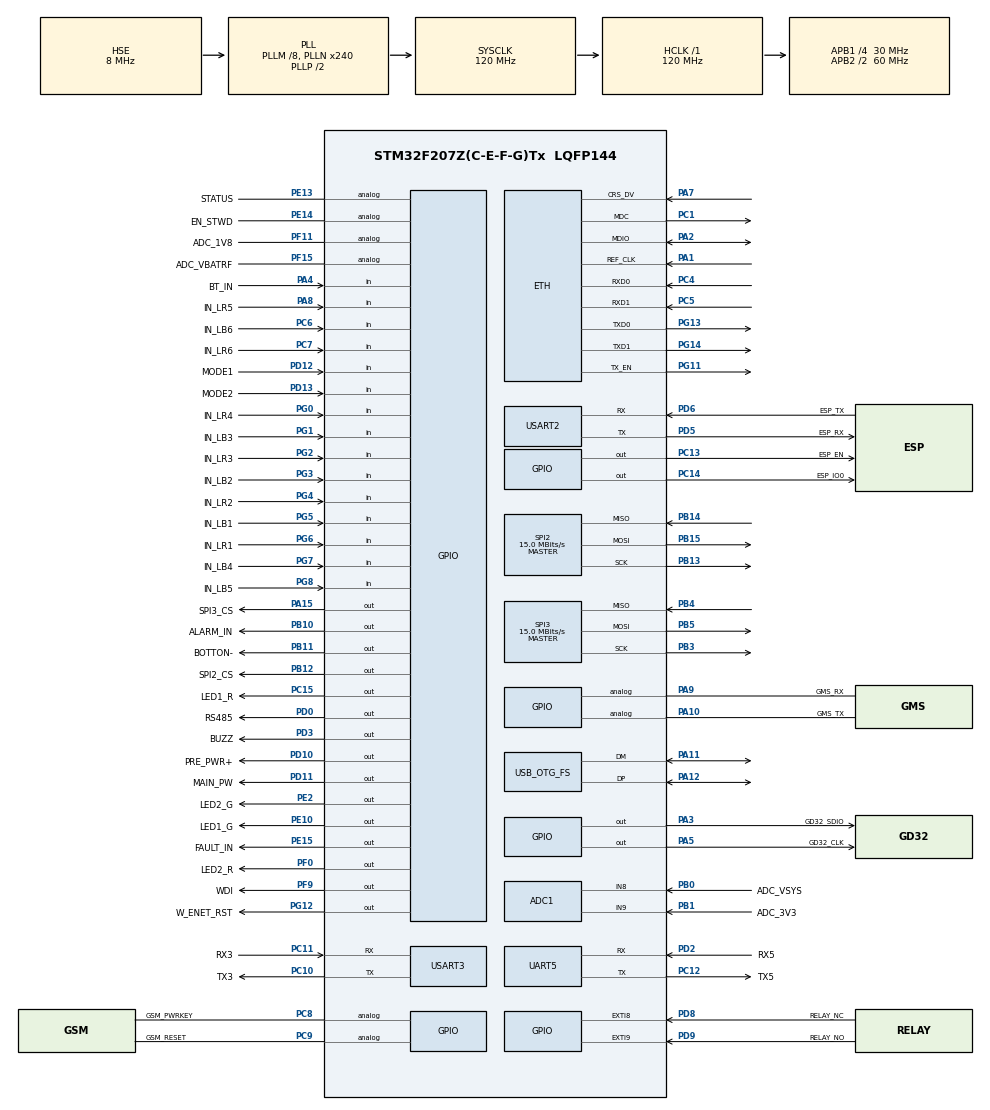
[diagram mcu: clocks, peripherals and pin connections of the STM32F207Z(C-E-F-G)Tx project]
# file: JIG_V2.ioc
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ADC1.Channel-1\#ChannelRegularConversion=ADC_CHANNEL_8
ADC1.Channel-2\#ChannelRegularConversion=ADC_CHANNEL_9
ADC1.ContinuousConvMode=ENABLE
ADC1.DMAContinuousRequests=ENABLE
ADC1.NbrOfConversion=2
ADC1.NbrOfConversionFlag=1
ADC1.Rank-1\#ChannelRegularConversion=1
ADC1.Rank-2\#ChannelRegularConversion=2
ADC1.SamplingTime-1\#ChannelRegularConversion=ADC_SAMPLETIME_480CYCLES
ADC1.SamplingTime-2\#ChannelRegularConversion=ADC_SAMPLETIME_480CYCLES
ADC1.master=1
Dma.ADC1.6.Direction=DMA_PERIPH_TO_MEMORY
Dma.ADC1.6.FIFOMode=DMA_FIFOMODE_DISABLE
Dma.ADC1.6.Instance=DMA2_Stream0
Dma.ADC1.6.MemDataAlignment=DMA_MDATAALIGN_HALFWORD
Dma.ADC1.6.MemInc=DMA_MINC_ENABLE
Dma.ADC1.6.Mode=DMA_CIRCULAR
Dma.ADC1.6.PeriphDataAlignment=DMA_PDATAALIGN_HALFWORD
Dma.ADC1.6.PeriphInc=DMA_PINC_DISABLE
Dma.ADC1.6.Priority=DMA_PRIORITY_LOW
Dma.Request0=USART2_TX
Dma.Request1=USART2_RX
Dma.Request2=SPI3_RX
Dma.Request3=SPI3_TX
Dma.Request4=SPI2_RX
Dma.Request5=SPI2_TX
Dma.Request6=ADC1
Dma.SPI2_RX.4.Direction=DMA_PERIPH_TO_MEMORY
Dma.SPI2_RX.4.FIFOMode=DMA_FIFOMODE_DISABLE
Dma.SPI2_RX.4.Instance=DMA1_Stream3
Dma.SPI2_RX.4.MemDataAlignment=DMA_MDATAALIGN_BYTE
Dma.SPI2_RX.4.MemInc=DMA_MINC_ENABLE
Dma.SPI2_RX.4.Mode=DMA_CIRCULAR
Dma.SPI2_RX.4.PeriphDataAlignment=DMA_PDATAALIGN_BYTE
Dma.SPI2_RX.4.PeriphInc=DMA_PINC_DISABLE
Dma.SPI2_RX.4.Priority=DMA_PRIORITY_LOW
Dma.SPI2_TX.5.Direction=DMA_MEMORY_TO_PERIPH
Dma.SPI2_TX.5.FIFOMode=DMA_FIFOMODE_DISABLE
Dma.SPI2_TX.5.Instance=DMA1_Stream4
Dma.SPI2_TX.5.MemDataAlignment=DMA_MDATAALIGN_BYTE
Dma.SPI2_TX.5.MemInc=DMA_MINC_ENABLE
Dma.SPI2_TX.5.Mode=DMA_NORMAL
Dma.SPI2_TX.5.PeriphDataAlignment=DMA_PDATAALIGN_BYTE
Dma.SPI2_TX.5.PeriphInc=DMA_PINC_DISABLE
Dma.SPI2_TX.5.Priority=DMA_PRIORITY_LOW
Dma.SPI3_RX.2.Direction=DMA_PERIPH_TO_MEMORY
Dma.SPI3_RX.2.FIFOMode=DMA_FIFOMODE_DISABLE
Dma.SPI3_RX.2.Instance=DMA1_Stream0
Dma.SPI3_RX.2.MemDataAlignment=DMA_MDATAALIGN_BYTE
Dma.SPI3_RX.2.MemInc=DMA_MINC_ENABLE
Dma.SPI3_RX.2.Mode=DMA_NORMAL
Dma.SPI3_RX.2.PeriphDataAlignment=DMA_PDATAALIGN_BYTE
Dma.SPI3_RX.2.PeriphInc=DMA_PINC_DISABLE
Dma.SPI3_RX.2.Priority=DMA_PRIORITY_LOW
Dma.SPI3_TX.3.Direction=DMA_MEMORY_TO_PERIPH
Dma.SPI3_TX.3.FIFOMode=DMA_FIFOMODE_DISABLE
Dma.SPI3_TX.3.Instance=DMA1_Stream7
Dma.SPI3_TX.3.MemDataAlignment=DMA_MDATAALIGN_BYTE
Dma.SPI3_TX.3.MemInc=DMA_MINC_ENABLE
Dma.SPI3_TX.3.Mode=DMA_NORMAL
Dma.SPI3_TX.3.PeriphDataAlignment=DMA_PDATAALIGN_BYTE
Dma.SPI3_TX.3.PeriphInc=DMA_PINC_DISABLE
Dma.SPI3_TX.3.Priority=DMA_PRIORITY_LOW
Dma.USART2_RX.1.Direction=DMA_PERIPH_TO_MEMORY
Dma.USART2_RX.1.FIFOMode=DMA_FIFOMODE_DISABLE
Dma.USART2_RX.1.Instance=DMA1_Stream5
Dma.USART2_RX.1.MemDataAlignment=DMA_MDATAALIGN_BYTE
Dma.USART2_RX.1.MemInc=DMA_MINC_ENABLE
Dma.USART2_RX.1.Mode=DMA_CIRCULAR
Dma.USART2_RX.1.PeriphDataAlignment=DMA_PDATAALIGN_BYTE
Dma.USART2_RX.1.PeriphInc=DMA_PINC_DISABLE
Dma.USART2_RX.1.Priority=DMA_PRIORITY_LOW
Dma.USART2_TX.0.Direction=DMA_MEMORY_TO_PERIPH
Dma.USART2_TX.0.FIFOMode=DMA_FIFOMODE_DISABLE
Dma.USART2_TX.0.Instance=DMA1_Stream6
Dma.USART2_TX.0.MemDataAlignment=DMA_MDATAALIGN_BYTE
Dma.USART2_TX.0.MemInc=DMA_MINC_ENABLE
Dma.USART2_TX.0.Mode=DMA_NORMAL
Dma.USART2_TX.0.PeriphDataAlignment=DMA_PDATAALIGN_BYTE
Dma.USART2_TX.0.PeriphInc=DMA_PINC_DISABLE
Dma.USART2_TX.0.Priority=DMA_PRIORITY_LOW
ETH.AutoNegotiation=ETH_AUTONEGOTIATION_DISABLE
ETH.MediaInterface=ETH_MEDIA_INTERFACE_RMII
ETH.PHY_Name_RMII=DP83848_PHY_ADDRESS
ETH.RxMode=ETH_RXINTERRUPT_MODE
FATFS._MAX_SS=4096
FATFS._USE_LABEL=1
FATFS._USE_LFN=2
FREERTOS.INCLUDE_vTaskDelayUntil=1
FREERTOS.Tasks01=defaultTask,0,256,StartDefaultTask,Default,NULL,Dynamic,NULL,NULL
FREERTOS.configMINIMAL_STACK_SIZE=256
FREERTOS.configTOTAL_HEAP_SIZE=48000
FREERTOS.configUSE_NEWLIB_REENTRANT=1
IWDG.Prescaler=IWDG_PRESCALER_256
IWDG.Reload=3750
LWIP.LWIP_HTTPD=1
LWIP.MEM_SIZE=1024*10
LWIP.Version=v2.0.3_Cube
Mcu.Family=STM32F2
Mcu.Name=STM32F207Z(C-E-F-G)Tx
Mcu.Package=LQFP144
NVIC.DMA1_Stream0_IRQn=true\:5\:0\:false\:false\:true\:true\:false\:true\:true
NVIC.DMA1_Stream3_IRQn=true\:5\:0\:false\:false\:true\:true\:false\:true\:true
NVIC.DMA1_Stream4_IRQn=true\:5\:0\:false\:false\:true\:true\:false\:true\:true
NVIC.DMA1_Stream5_IRQn=true\:5\:0\:false\:false\:true\:true\:false\:true\:true
NVIC.DMA1_Stream6_IRQn=true\:5\:0\:false\:false\:true\:true\:false\:true\:true
NVIC.DMA1_Stream7_IRQn=true\:5\:0\:false\:false\:true\:true\:false\:true\:true
NVIC.DMA2_Stream0_IRQn=true\:5\:0\:false\:false\:true\:true\:false\:true\:true
NVIC.ETH_IRQn=true\:5\:0\:false\:false\:true\:true\:true\:true\:true
NVIC.EXTI9_5_IRQn=true\:5\:0\:false\:false\:true\:false\:true\:true\:true
NVIC.OTG_FS_IRQn=true\:5\:0\:false\:false\:true\:true\:true\:true\:true
NVIC.PriorityGroup=NVIC_PRIORITYGROUP_4
NVIC.SPI2_IRQn=true\:5\:0\:false\:false\:true\:true\:true\:true\:true
NVIC.SPI3_IRQn=true\:5\:0\:false\:false\:true\:true\:true\:true\:true
NVIC.TIM2_IRQn=true\:15\:0\:false\:false\:true\:false\:false\:true\:true
NVIC.TimeBase=TIM2_IRQn
NVIC.TimeBaseIP=TIM2
NVIC.UART5_IRQn=true\:5\:0\:false\:false\:true\:true\:true\:true\:true
NVIC.USART2_IRQn=true\:5\:0\:false\:false\:true\:true\:true\:true\:true
NVIC.USART3_IRQn=true\:5\:0\:false\:false\:true\:true\:true\:true\:true
PA1.Mode=RMII
PA1.Signal=ETH_REF_CLK
PA10.GPIO_Label=GMS_TX
PA10.Signal=GPIO_Analog
PA11.Mode=Device_Only
PA11.Signal=USB_OTG_FS_DM
PA12.Mode=Device_Only
PA12.Signal=USB_OTG_FS_DP
PA13.Mode=Serial_Wire
PA13.Signal=SYS_JTMS-SWDIO
PA14.Mode=Serial_Wire
PA14.Signal=SYS_JTCK-SWCLK
PA15.GPIO_Label=SPI3_CS
PA15.Signal=GPIO_Output
PA2.Mode=RMII
PA2.Signal=ETH_MDIO
PA3.GPIO_Label=GD32_SDIO
PA3.Signal=GPIO_Output
PA4.GPIO_Label=BT_IN
PA4.GPIO_PuPd=GPIO_PULLUP
PA4.Signal=GPIO_Input
PA5.GPIO_Label=GD32_CLK
PA5.Signal=GPIO_Output
PA7.Mode=RMII
PA7.Signal=ETH_CRS_DV
PA8.GPIO_Label=IN_LR5
PA8.Signal=GPIO_Input
PA9.GPIO_Label=GMS_RX
PA9.Signal=GPIO_Analog
PB0.GPIO_Label=ADC_VSYS
PB0.Signal=ADCx_IN8
PB1.GPIO_Label=ADC_3V3
PB1.Signal=ADCx_IN9
PB10.GPIO_Label=ALARM_IN
PB10.Signal=GPIO_Output
PB11.GPIO_Label=BOTTON-
PB11.Signal=GPIO_Output
PB12.GPIO_Label=SPI2_CS
PB12.Signal=GPIO_Output
PB13.Mode=Full_Duplex_Master
PB13.Signal=SPI2_SCK
PB14.Mode=Full_Duplex_Master
PB14.Signal=SPI2_MISO
PB15.Mode=Full_Duplex_Master
PB15.Signal=SPI2_MOSI
PB3.Mode=Full_Duplex_Master
PB3.Signal=SPI3_SCK
PB4.Mode=Full_Duplex_Master
PB4.Signal=SPI3_MISO
PB5.Mode=Full_Duplex_Master
PB5.Signal=SPI3_MOSI
PC1.Mode=RMII
PC1.Signal=ETH_MDC
PC10.GPIO_Label=TX3
PC10.Mode=Asynchronous
PC10.Signal=USART3_TX
PC11.GPIO_Label=RX3
PC11.Mode=Asynchronous
PC11.Signal=USART3_RX
PC12.GPIO_Label=TX5
PC12.Mode=Asynchronous
PC12.Signal=UART5_TX
PC13.GPIO_Label=ESP_EN
PC13.Signal=GPIO_Output
PC14-OSC32_IN.GPIO_Label=ESP_IO0
PC14-OSC32_IN.Signal=GPIO_Output
PC15-OSC32_OUT.GPIO_Label=LED1_R
PC15-OSC32_OUT.Signal=GPIO_Output
PC4.Mode=RMII
PC4.Signal=ETH_RXD0
PC5.Mode=RMII
PC5.Signal=ETH_RXD1
PC6.GPIO_Label=IN_LB6
PC6.Signal=GPIO_Input
PC7.GPIO_Label=IN_LR6
PC7.Signal=GPIO_Input
PC8.GPIO_Label=GSM_PWRKEY
PC8.Signal=GPIO_Analog
PC9.GPIO_Label=GSM_RESET
PC9.Signal=GPIO_Analog
PD0.GPIO_Label=RS485
PD0.GPIO_PuPd=GPIO_PULLUP
PD0.Signal=GPIO_Output
PD10.GPIO_Label=PRE_PWR+
PD10.Signal=GPIO_Output
PD11.GPIO_Label=MAIN_PW
PD11.Signal=GPIO_Output
PD12.GPIO_Label=MODE1
PD12.Signal=GPIO_Input
PD13.GPIO_Label=MODE2
PD13.Signal=GPIO_Input
PD2.GPIO_Label=RX5
PD2.Mode=Asynchronous
PD2.Signal=UART5_RX
PD3.GPIO_Label=BUZZ
PD3.Signal=GPIO_Output
PD5.GPIO_Label=ESP_RX
PD5.Mode=Asynchronous
PD5.Signal=USART2_TX
PD6.GPIO_Label=ESP_TX
PD6.Mode=Asynchronous
PD6.Signal=USART2_RX
PD8.GPIO_Label=RELAY_NC
PD8.Signal=GPXTI8
PD9.GPIO_Label=RELAY_NO
PD9.Signal=GPXTI9
PE10.GPIO_Label=LED1_G
PE10.Signal=GPIO_Output
PE13.GPIO_Label=STATUS
PE13.Signal=GPIO_Analog
PE14.GPIO_Label=EN_STWD
PE14.Signal=GPIO_Analog
PE15.GPIO_Label=FAULT_IN
PE15.Signal=GPIO_Output
PE2.GPIO_Label=LED2_G
PE2.Signal=GPIO_Output
PF0.GPIO_Label=LED2_R
PF0.Signal=GPIO_Output
PF11.GPIO_Label=ADC_1V8
PF11.Signal=GPIO_Analog
PF15.GPIO_Label=ADC_VBATRF
PF15.Signal=GPIO_Analog
PF9.GPIO_Label=WDI
PF9.Signal=GPIO_Output
PG0.GPIO_Label=IN_LR4
PG0.Signal=GPIO_Input
PG1.GPIO_Label=IN_LB3
PG1.Signal=GPIO_Input
PG11.Mode=RMII
PG11.Signal=ETH_TX_EN
PG12.GPIO_Label=W_ENET_RST
PG12.GPIO_PuPd=GPIO_PULLUP
PG12.PinState=GPIO_PIN_SET
PG12.Signal=GPIO_Output
PG13.Mode=RMII
PG13.Signal=ETH_TXD0
PG14.Mode=RMII
PG14.Signal=ETH_TXD1
PG2.GPIO_Label=IN_LR3
PG2.Signal=GPIO_Input
PG3.GPIO_Label=IN_LB2
PG3.Signal=GPIO_Input
PG4.GPIO_Label=IN_LR2
PG4.Signal=GPIO_Input
PG5.GPIO_Label=IN_LB1
PG5.Signal=GPIO_Input
PG6.GPIO_Label=IN_LR1
PG6.Signal=GPIO_Input
PG7.GPIO_Label=IN_LB4
PG7.Signal=GPIO_Input
PG8.GPIO_Label=IN_LB5
PG8.Signal=GPIO_Input
PH0-OSC_IN.Mode=HSE-External-Oscillator
PH0-OSC_IN.Signal=RCC_OSC_IN
PH1-OSC_OUT.Mode=HSE-External-Oscillator
PH1-OSC_OUT.Signal=RCC_OSC_OUT
ProjectManager.HeapSize=0x200
ProjectManager.StackSize=0x400
ProjectManager.TargetToolchain=STM32CubeIDE
RCC.48MHZClocksFreq_Value=48000000
RCC.AHBFreq_Value=120000000
RCC.APB1CLKDivider=RCC_HCLK_DIV4
RCC.APB1Freq_Value=30000000
RCC.APB1TimFreq_Value=60000000
RCC.APB2CLKDivider=RCC_HCLK_DIV2
RCC.APB2Freq_Value=60000000
RCC.APB2TimFreq_Value=120000000
RCC.CortexFreq_Value=120000000
RCC.HCLKFreq_Value=120000000
RCC.HSE_VALUE=8000000
RCC.HSI_VALUE=16000000
RCC.LSE_VALUE=32768
RCC.PLLM=8
RCC.PLLN=240
RCC.PLLQ=5
RCC.PLLSourceVirtual=RCC_PLLSOURCE_HSE
RCC.SYSCLKFreq_VALUE=120000000
RCC.SYSCLKSource=RCC_SYSCLKSOURCE_PLLCLK
RCC.VCOOutputFreq_Value=240000000
RTC.AsynchPrediv=125
SH.ADCx_IN8.0=ADC1_IN8,IN8
SH.ADCx_IN9.0=ADC1_IN9,IN9
SPI2.CalculateBaudRate=15.0 MBits/s
SPI2.Direction=SPI_DIRECTION_2LINES
SPI2.Mode=SPI_MODE_MASTER
SPI2.VirtualType=VM_MASTER
SPI3.CalculateBaudRate=15.0 MBits/s
SPI3.Direction=SPI_DIRECTION_2LINES
SPI3.Mode=SPI_MODE_MASTER
SPI3.VirtualType=VM_MASTER
UART5.VirtualMode=Asynchronous
USART2.VirtualMode=VM_ASYNC
USART3.VirtualMode=VM_ASYNC
USB_DEVICE.CLASS_NAME_FS=MSC
USB_DEVICE.VirtualMode-MSC_FS=Msc
USB_DEVICE.VirtualModeFS=Msc_FS
USB_OTG_FS.VirtualMode=Device_Only
VP_FATFS_VS_Generic.Mode=User_defined
VP_FREERTOS_VS_CMSIS_V1.Mode=CMSIS_V1
VP_IWDG_VS_IWDG.Mode=IWDG_Activate
VP_LWIP_VS_Enabled.Mode=Enabled
VP_RTC_VS_RTC_Activate.Mode=RTC_Enabled
VP_RTC_VS_RTC_Calendar.Mode=RTC_Calendar
VP_SYS_VS_tim2.Mode=TIM2
VP_USB_DEVICE_VS_USB_DEVICE_MSC_FS.Mode=MSC_FS
board=custom

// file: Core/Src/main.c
/* USER CODE BEGIN Header */
/**
  ******************************************************************************
  * @file           : main.c
  * @brief          : Main program body
  ******************************************************************************
  * @attention
  *
  * Copyright (c) 2022 STMicroelectronics.
  * All rights reserved.
  *
  * This software is licensed under terms that can be found in the LICENSE file
  * in the root directory of this software component.
  * If no LICENSE file comes with this software, it is provided AS-IS.
  *
  ******************************************************************************
  */
/* USER CODE END Header */
#include "main.h"
#include "cmsis_os.h"
#include "adc.h"
#include "dma.h"
#include "fatfs.h"
#include "iwdg.h"
#include "lwip.h"
#include "rtc.h"
#include "spi.h"
#include "usart.h"
#include "usb_device.h"
#include "gpio.h"

/* USER CODE BEGIN Includes */
#include <stdbool.h>
#include "app_debug.h"
#include "Segger_RTT.h"
/* USER CODE END Includes */

/* USER CODE BEGIN PV */
uint16_t toggle_100_ms = 0;
/* USER CODE END PV */

void SystemClock_Config(void);
void MX_FREERTOS_Init(void);
/* USER CODE BEGIN PFP */
uint32_t sys_get_ms(void);
bool lock_debug(bool lock, uint32_t timeout_ms);
uint32_t rtt_tx(const void *buffer, uint32_t size);
static SemaphoreHandle_t m_lock_debug;
/* USER CODE END PFP */

int main(void)
{

  /* MCU Configuration--------------------------------------------------------*/

  /* Reset of all peripherals, Initializes the Flash interface and the Systick. */
  HAL_Init();

  /* Configure the system clock */
  SystemClock_Config();

  /* Initialize all configured peripherals */
  MX_GPIO_Init();
  MX_DMA_Init();
  MX_ADC1_Init();
//  MX_IWDG_Init();
  MX_RTC_Init();
  MX_SPI2_Init();
  MX_UART5_Init();
  MX_USART2_UART_Init();
  MX_USART3_UART_Init();
//  MX_FATFS_Init();
  MX_SPI3_Init();
  /* USER CODE BEGIN 2 */
  m_lock_debug = xSemaphoreCreateMutex();
  xSemaphoreGive(m_lock_debug);
  app_debug_init(sys_get_ms, lock_debug);
  app_debug_register_callback_print(rtt_tx);
  /* USER CODE END 2 */

  /* Call init function for freertos objects (in freertos.c) */
  MX_FREERTOS_Init();

  /* Start scheduler */
  osKernelStart();

  /* We should never get here as control is now taken by the scheduler */
  /* Infinite loop */
  while (1)
  {

  }
}

void SystemClock_Config(void)
{
  RCC_OscInitTypeDef RCC_OscInitStruct = {0};
  RCC_ClkInitTypeDef RCC_ClkInitStruct = {0};
  RCC_PeriphCLKInitTypeDef PeriphClkInitStruct = {0};

  /** Initializes the RCC Oscillators according to the specified parameters
  * in the RCC_OscInitTypeDef structure.
  */
  RCC_OscInitStruct.OscillatorType = RCC_OSCILLATORTYPE_LSI|RCC_OSCILLATORTYPE_HSE;
  RCC_OscInitStruct.HSEState = RCC_HSE_ON;
  RCC_OscInitStruct.LSIState = RCC_LSI_ON;
  RCC_OscInitStruct.PLL.PLLState = RCC_PLL_ON;
  RCC_OscInitStruct.PLL.PLLSource = RCC_PLLSOURCE_HSE;
  RCC_OscInitStruct.PLL.PLLM = 8;
  RCC_OscInitStruct.PLL.PLLN = 240;
  RCC_OscInitStruct.PLL.PLLP = RCC_PLLP_DIV2;
  RCC_OscInitStruct.PLL.PLLQ = 5;
  if (HAL_RCC_OscConfig(&RCC_OscInitStruct) != HAL_OK)
  {
    Error_Handler();
  }

  /** Initializes the CPU, AHB and APB buses clocks
  */
  RCC_ClkInitStruct.ClockType = RCC_CLOCKTYPE_HCLK|RCC_CLOCKTYPE_SYSCLK
                              |RCC_CLOCKTYPE_PCLK1|RCC_CLOCKTYPE_PCLK2;
  RCC_ClkInitStruct.SYSCLKSource = RCC_SYSCLKSOURCE_PLLCLK;
  RCC_ClkInitStruct.AHBCLKDivider = RCC_SYSCLK_DIV1;
  RCC_ClkInitStruct.APB1CLKDivider = RCC_HCLK_DIV4;
  RCC_ClkInitStruct.APB2CLKDivider = RCC_HCLK_DIV2;

  if (HAL_RCC_ClockConfig(&RCC_ClkInitStruct, FLASH_LATENCY_3) != HAL_OK)
  {
    Error_Handler();
  }
  PeriphClkInitStruct.PeriphClockSelection = RCC_PERIPHCLK_RTC;
  PeriphClkInitStruct.RTCClockSelection = RCC_RTCCLKSOURCE_LSI;
  if (HAL_RCCEx_PeriphCLKConfig(&PeriphClkInitStruct) != HAL_OK)
  {
    Error_Handler();
  }
}

/* USER CODE BEGIN 4 */
uint32_t sys_get_ms(void)
{
    return HAL_GetTick();
}

bool lock_debug(bool lock, uint32_t timeout_ms)
{
	if (lock)
		return xSemaphoreTake(m_lock_debug, timeout_ms);
	xSemaphoreGive(m_lock_debug);
	return true;
}
uint32_t rtt_tx(const void *buffer, uint32_t size)
{
    return SEGGER_RTT_Write(0, buffer, size);
}
/* USER CODE END 4 */

void HAL_TIM_PeriodElapsedCallback(TIM_HandleTypeDef *htim)
{
  if (htim->Instance == TIM2) {
    HAL_IncTick();
    toggle_100_ms++;
    HAL_GPIO_TogglePin (WDI_GPIO_Port, WDI_Pin);
  }
  /* USER CODE BEGIN Callback 1 */
  if (toggle_100_ms == 100)
    {
  	  toggle_100_ms = 0;
//  	  HAL_GPIO_TogglePin (ISO_IN1_GPIO_Port, ISO_IN1_Pin);
  	  HAL_GPIO_TogglePin (BOTTON__GPIO_Port, BOTTON__Pin);
  	  HAL_GPIO_TogglePin (MAIN_PW_GPIO_Port, MAIN_PW_Pin);
  	  HAL_GPIO_TogglePin (PRE_PWR__GPIO_Port, PRE_PWR__Pin);
  	  HAL_GPIO_TogglePin (ALARM_IN_GPIO_Port, ALARM_IN_Pin);
  	  HAL_GPIO_TogglePin (FAULT_IN_GPIO_Port, FAULT_IN_Pin);
    }
  /* USER CODE END Callback 1 */
}

void Error_Handler(void)
{
  __disable_irq();
  while (1)
  {
  }
}

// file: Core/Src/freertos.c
/* USER CODE BEGIN Header */
/**
  ******************************************************************************
  * File Name          : freertos.c
  * Description        : Code for freertos applications
  ******************************************************************************
  * @attention
  *
  * Copyright (c) 2022 STMicroelectronics.
  * All rights reserved.
  *
  * This software is licensed under terms that can be found in the LICENSE file
  * in the root directory of this software component.
  * If no LICENSE file comes with this software, it is provided AS-IS.
  *
  ******************************************************************************
  */
/* USER CODE END Header */

#include "FreeRTOS.h"
#include "task.h"
#include "main.h"
#include "cmsis_os.h"

/* USER CODE BEGIN Includes */
#include "usbd_storage_if.h"
#include "tusb.h"
#include "app_debug.h"
#include "fatfs.h"
#include "lwrb.h"
#include <stdbool.h>
#include "FreeRTOSConfig.h"
#include "semphr.h"
#include "task.h"
#include "event_groups.h"
#include "esp_loader.h"
#include "example_common.h"
#include "md5_hash.h"
#include "app_btn.h"
#include "utilities.h"
#include "usart.h"
#include "stm32_port.h"
#include "app_ethernet.h"
#include "ethernetif.h"
#include "lwip/init.h"
#include "lwip/netif.h"
#include "lwip/timeouts.h"
#include "netif/etharp.h"
#include "lwip.h"
#include "stdio.h"
#include "app_http.h"
#include "lwip/dns.h"
#include "mqtt_client.h"
#include "min.h"
#include "min_id.h"
#include "ringBuffer.h"
#include "adc.h"
#include "sntp.h"
#include "rtc.h"
#include "time.h"
#include "app_cli.h"
#include "iwdg.h"
#include "ff.h"
#include "spi.h"
#include "app_spi_flash.h"
#include "app_drv_spi.h"
/* USER CODE END Includes */

/* USER CODE BEGIN PTD */

typedef struct
{
    uint8_t year;
    uint8_t month;
    uint8_t day;
    uint8_t hour;
    uint8_t minute;
    uint8_t second;
} date_time_t;

typedef enum
{
	NOT_CONNECTED,
	CONNECT,
	ETHERNET_CONNECTED
} ETHERNET_STATE;
typedef union
{
	struct
	{
		uint8_t led1_ok: 1;
		uint8_t led2_ok: 1;
		uint8_t led3_ok: 1;
		uint8_t led4_ok: 1;
		uint8_t led5_ok: 1;
		uint8_t led6_ok: 1;
		uint16_t reserve:2;
	}res;
	uint8_t led_res;
} led_result_t;
typedef union
{
	struct
	{
		uint32_t rs485: 1;
		uint32_t rs232: 1;
		uint32_t test_wd_ok: 1;
		uint32_t sim_ok :1;
		uint32_t temper_ok: 1;
//		uint32_t vin_ok: 1;
		uint32_t vbat_ok: 1;
		uint32_t v1v8_ok: 1;
		uint32_t v3v3_ok: 1;
//		uint32_t v5v_ok: 1;
		uint32_t vgsm4v2_ok: 1;
		uint32_t charge_ok: 1;
		uint32_t alarm_ok:1;
		uint32_t fault_ok:1;
		uint32_t relay0_ok: 1;
		uint32_t relay1_ok: 1;
//		uint32_t buttonTest_ok: 1;
//		uint32_t sosButton_ok: 1;
		uint32_t vsys_ok:1;
		uint32_t reserved : 17;
	} result;
	uint32_t value;
}__attribute__((packed)) func_test_t;
typedef union
{

	struct

	{

		uint16_t eth : 1;

		uint16_t wifi : 1;

		uint16_t gsm : 1;

		uint16_t server : 1;

		uint16_t input0_pass : 1;

		uint16_t input1_pass : 1;

		uint16_t input2_pass : 1;

		uint16_t input3_pass : 1;

		uint16_t button_pass : 1;

		uint16_t main_power_pass : 1;

		uint16_t backup_power_pass : 1;

		uint16_t reserve : 5;

	} name;

	uint16_t value;

} __attribute__((packed)) jig_peripheral_t;
typedef struct

{

	char gsm_imei[16];

	char sim_imei[16];

	uint8_t mac[6];

	uint16_t gsm_voltage;

	jig_peripheral_t peripheral;

    uint8_t temperature;

    uint8_t device_type;  // 0 = "B01", 1 = "B02"

    uint8_t fw_version[3];  // Major.minor.build

    uint8_t hw_version[3];  // Major.minor.build

    func_test_t test_result;

    uint32_t timestamp;

    led_result_t led_result;
} __attribute__((packed)) jig_value_t;

typedef struct
{
	uint16_t vin_max;
	uint16_t vin_min;
	uint16_t vbat_max;
	uint16_t vbat_min;
	uint16_t v1v8_max;
	uint16_t v1v8_min;
	uint16_t v3v3_max;
	uint16_t v3v3_min;
	uint16_t v5v_max;
	uint16_t v5v_min;
	uint16_t v4v2_max;
	uint16_t v4v2_min;
	uint16_t vsys_max;
	uint16_t vsys_min;
} __attribute__((packed)) test_info;
/* USER CODE END PTD */

/* USER CODE BEGIN PD */
#define USB_CDC_TX_RING_BUFFER_SIZE		1024
// BUTTON DEFINE
#define BIT_EVENT_GROUP_BT_IN_PRESSED        (1 << 0)
#define HW_BTN_CONFIG                                       \
{                                                           \
    /* PinName       Last state   Idle level*/              \
	{0,				1,				1						}}

#define TIMEOUT 8000 // TEST TIMEOUT
static const uint8_t day_in_month[12] = {31, 29, 31, 30, 31, 30, 31, 31, 30, 31, 30, 31};
#define FIRSTYEAR 2000 // start year
#define FIRSTDAY 6     // 0 = Sunday

// WDT DEFINE
EventGroupHandle_t m_wdg_event_group = NULL;
#define defaultTaskB 	(1 << 0)
#define cdcTaskB 		(1 << 1)
#define usbTaskB 		(1 << 2)
#define flashTaskB 		(1 << 3)
#define netTaskB 		(1 << 4)

/* USER CODE END PD */

/* USER CODE BEGIN PM */
static EventBits_t uxBits;
/* USER CODE END PM */

/* USER CODE BEGIN Variables */

/**************        BUTTON VAR               ***********/
	static app_btn_hw_config_t m_button_cfg[] = HW_BTN_CONFIG;
	static EventGroupHandle_t m_button_event_group = NULL;
/**********************************************************/

/*********************      flash task var             ***********************/
	static TaskHandle_t m_task_connect_handle = NULL;

	static example_binaries_t m_binary;
	static char m_file_address[128];
	volatile uint32_t led_busy_toggle = 0;

	static const char *info_file = "info.txt";
	static const char *bootloader_file = "bootloader.bin";
	static const char *firmware_file = "fire_safe_normal.bin";
	static const char *ota_file = "ota_data_initial.bin";
	static const char *partition_file = "partition-table.bin";

	static const char *chip_des[] = {"ESP8266", "ESP32", "ESP32S2", "ESP32C3", "ESP32S3", "ESP32C2", "ESP32H2", "UNKNOWN"};
/***********************************************************************************************************/

//************************** MD5 CRC CONFIG VAR **********************************************************//
	static uint8_t m_buffer[4096];
	static MD5Context_t md5_context;
	static esp_loader_config_t m_loader_cfg =
	{
		.baud_rate = 115200,
		.reset_trigger_pin = ESP_EN_Pin,
		.gpio0_trigger_pin = ESP_IO0_Pin,
		.buffer = m_buffer,
		.buffer_size = 4096,
		.sync_timeout = 100,
		.trials = 10,
		.md5_context = &md5_context
	};
//***********************************************************************************************//

/*************************** 	  FLASH DISK VARIABLE        *************************************************************/
	BYTE gFSWork[_MAX_SS];
	UINT br, bw;  // File read/write count
	UINT fbr, fbw;  // File read/write count
	FRESULT flash_res;
	bool m_disk_is_mounted = false;
/***********************************************************************************************************************/

/********************************  	 CDC TASK VAR     *****************************************************************/
	StackType_t  cdc_stack[configMINIMAL_STACK_SIZE];
	StaticTask_t cdc_taskdef;
/**********************************************************************************************************************/

//********************************    tiny USB TASK VAR     ********************************************************//
	static TaskHandle_t m_USB_handle = NULL;
	bool tusb_init_flag = false;

//********************************************************************************************************************//

/*********************8*************       NET VAR    ******************************************************************/
	struct netif g_netif;
	static TaskHandle_t m_task_handle_protocol = NULL; //NET APP TASK
	osThreadId DHCP_id;
	SemaphoreHandle_t hHttpStart;
	xQueueHandle httpQueue;
	bool send_offline_file = false;
	SemaphoreHandle_t sent_an_offline_file;
/*********************************************************************************************************************/

//***************************  TESTING TASK VAR   *********************************//
	static TaskHandle_t mTest_Handle_t = NULL;
	char gsm_imei[16];
	char sim_imei[16];
	uint8_t MAC[6]={0x00, 0x00, 0x00, 0x00, 0x00, 0x00};
	uint8_t lastMAC[6]={0x00, 0x00, 0x00, 0x00, 0x00, 0x00};
	static jig_value_t *rx_value;
	static jig_value_t *to_send_value;
	jig_peripheral_t jig_result;
	bool get_jig_info = false;
	static func_test_t test_res;
	bool allPassed = false;
	static const char *test_info_file = "test_info.txt";
	char json_send_to_sever[1024];
	test_info voltage_info;
	uint8_t V_info_buff[512];
	uint8_t relay_toggle_0;
	uint8_t relay_toggle_1;
	bool ready_send_to_sever = false;
	// adc read var
	uint16_t ADCScan[2];
	uint8_t idle_detect;

	//*********************LED DETECT VAR ************************//

	static GPIO_PinState led_status[12];
//	static uint8_t res_count[6];
	#define LR1 0
	#define LR2 1
	#define LR3 2
	#define LR4 3
	#define LR5 4
	#define LR6 5
	#define LB1 6
	#define LB2 7
	#define LB3 8
	#define LB4 9
	#define LB5 10
	#define LB6 11
	static led_result_t led_detect =
		{
			.res.led1_ok = 0,
			.res.led2_ok = 0,
			.res.led3_ok = 0,
			.res.led4_ok = 0,
			.res.led5_ok = 0,
			.res.led6_ok = 0,
			.res.reserve = 0b11
		};

//*****************************************************************************//

//********************************* MIN PROTOCOL VAR**********************//
	lwrb_t m_ringbuffer_host_rx;
	uint8_t m_rs232_host_buffer[512];
	static uint8_t m_min_rx_buffer[256];
	static min_context_t m_min_context;
	static min_frame_cfg_t m_min_setting = MIN_DEFAULT_CONFIG();
//*******************************************************************//
	// ******************** RING BUFFER********************************//
	uint8_t rs485ringBuffer [256];
	lwrb_t m_ringbuffer_rs485_rx;
//******************************************************************//

//************************* TIME PROTOCOL PRO AND VAR***********************************//
	void lwip_sntp_recv_cb (uint32_t time);
//*******************************************************************************************//

//************************** RTC VAR*******************************//

  RTC_TimeTypeDef sTime = {0};
  RTC_DateTypeDef sDate = {0};
  RTC_TimeTypeDef sTimeToSend = {0};
  RTC_DateTypeDef sDateToSend = {0};
//  RTC_HandleTypeDef hrtc1;
  static date_time_t date_time;
//********************************************************************//

/* USER CODE END Variables */
osThreadId defaultTaskHandle;

/* USER CODE BEGIN FunctionPrototypes */
//***************************************   TASK PFT *****************************************************************//
void cdc_task(void* params);

void usb_task (void* params);

void flash_task(void *argument);

void testing_task (void *arg);

//***************************************************************************************************************//

// ****************************************** RTC PFP****************************************************************//
void reInitRTC ( RTC_TimeTypeDef sTime, RTC_DateTypeDef sDate);

static void initialize_stnp(void);

static uint32_t convert_date_time_to_second(date_time_t *t);

static void convert_second_to_date_time(uint32_t sec, date_time_t *t, uint8_t Calyear);
//*******************************************************************************************************************//

/*************************************      BUTTON FP          *********************************************************/
void button_initialize(uint32_t button_num);

uint32_t btn_read(uint32_t pin);

void on_btn_pressed(int number, int event, void * pData);

void on_btn_release(int number, int event, void * pData);

void on_btn_hold(int number, int event, void * pData);

static void on_btn_hold_so_long(int index, int event, void * pData);
/************************************************************************************************************************/

//*******************************************  ETHERNET PFP      ********************************************************/
void Netif_Config (bool restart);
void net_task(void *argument);

/***********************************************************************************************************************/

//************************************  TEST PROTOTYPE    **************************************************************//

int16_t json_build(jig_value_t *value, func_test_t * test, char *json_str);

void Get_test_result (jig_value_t * value, jig_peripheral_t* peripheral);

//void make_string_from_mac(char* str);
void min_rx_callback (void *min_context , min_msg_t *frame);

bool RS232_tx (void *ctx, uint8_t byte);

void volTest(void);

bool PassTest (jig_value_t * value);

void send_test_command(min_msg_t * test_command);

bool RS232_tx (void *ctx, uint8_t byte);

void Get_sim_imei(jig_value_t * value, char *sim_imei);

void Get_gsm_imei(jig_value_t * value, char *gsm_imei);

void Get_MAC(jig_value_t * value, uint8_t *MAC);

void check_led_status(void);

//********************************************************************************************************************//

/* USER CODE END FunctionPrototypes */

void StartDefaultTask(void const * argument);

extern void MX_LWIP_Init(void);
extern void MX_USB_DEVICE_Init(void);
void MX_FREERTOS_Init(void); /* (MISRA C 2004 rule 8.1) */

/* GetIdleTaskMemory prototype (linked to static allocation support) */
void vApplicationGetIdleTaskMemory( StaticTask_t **ppxIdleTaskTCBBuffer, StackType_t **ppxIdleTaskStackBuffer, uint32_t *pulIdleTaskStackSize );

/* USER CODE BEGIN GET_IDLE_TASK_MEMORY */
static StaticTask_t xIdleTaskTCBBuffer;
static StackType_t xIdleStack[configMINIMAL_STACK_SIZE];

void vApplicationGetIdleTaskMemory( StaticTask_t **ppxIdleTaskTCBBuffer, StackType_t **ppxIdleTaskStackBuffer, uint32_t *pulIdleTaskStackSize )
{
  *ppxIdleTaskTCBBuffer = &xIdleTaskTCBBuffer;
  *ppxIdleTaskStackBuffer = &xIdleStack[0];
  *pulIdleTaskStackSize = configMINIMAL_STACK_SIZE;
  /* place for user code */
}
/* USER CODE END GET_IDLE_TASK_MEMORY */

void MX_FREERTOS_Init(void) {

  /* Create the thread(s) */
  /* definition and creation of defaultTask */
  osThreadDef(defaultTask, StartDefaultTask, osPriorityNormal, 0, 256);
  defaultTaskHandle = osThreadCreate(osThread(defaultTask), NULL);

}

void StartDefaultTask(void const * argument)
{
  /* init code for LWIP */
//  MX_LWIP_Init();

  /* init code for USB_DEVICE */
//  MX_USB_DEVICE_Init();
  /* USER CODE BEGIN StartDefaultTask */

	GPIO_InitTypeDef GPIO_InitStruct = {0};
	GPIO_InitStruct.Pin = GPIO_PIN_11|GPIO_PIN_12;
	GPIO_InitStruct.Mode = GPIO_MODE_OUTPUT_PP;
	GPIO_InitStruct.Pull = GPIO_NOPULL;
	GPIO_InitStruct.Speed = GPIO_SPEED_FREQ_LOW;
	HAL_GPIO_Init(GPIOA, &GPIO_InitStruct);

	HAL_GPIO_WritePin(GPIOA, GPIO_PIN_11, GPIO_PIN_RESET);
	HAL_GPIO_WritePin(GPIOA, GPIO_PIN_12, GPIO_PIN_RESET);
	/********  DISCONNECT USB TO MAKE RENUM EVENT  *********/
	MX_FATFS_Init();

	vTaskDelay(500);		// time for usb renum

	HAL_GPIO_WritePin(GPIOA, GPIO_PIN_11, GPIO_PIN_SET);
	HAL_GPIO_WritePin(GPIOA, GPIO_PIN_12, GPIO_PIN_SET);

	GPIO_InitStruct.Pin = GPIO_PIN_11|GPIO_PIN_12;
	GPIO_InitStruct.Mode = GPIO_MODE_INPUT;
	GPIO_InitStruct.Pull = GPIO_NOPULL;
	GPIO_InitStruct.Speed = GPIO_SPEED_FREQ_LOW;
	HAL_GPIO_Init(GPIOA, &GPIO_InitStruct);
	/*            RECONNECT USB         */
	//************************* INIT FUNCTIONS **************************//
	MX_USB_DEVICE_Init();
//***********************     MOUNT FLASH DISK	*************************//
	flash_res = f_mount(&USERFatFS, USERPath, 1);
	  if (flash_res != FR_OK)
	  {
		DEBUG_WARN("Mount flash fail\r\n");
		flash_res = f_mkfs(USERPath, FM_ANY, 0, gFSWork, sizeof gFSWork);
		flash_res = f_mount(&USERFatFS, USERPath, 1);
		if (flash_res == FR_OK)
		{
			m_disk_is_mounted = true;
			DEBUG_INFO ("format disk and mount again\r\n");
		}
		else
		{
			DEBUG_ERROR("Mount flash error\r\n");
		}
	  }
	  else
	  {
		m_disk_is_mounted = true;
		DEBUG_INFO ("Mount flash ok\r\n");
	  }
	  TCHAR label[32];
	  f_getlabel(USERPath, label, 0);
	  DEBUG_INFO("Label %s\r\n", label);
	  if (strcmp(label, "BSAFE JIG"))
	  {
		DEBUG_INFO("Set label\r\n");
		f_setlabel("BSAFE JIG");
	  }
//***********************************************************************//

//*************************** INIT BUTTON APP**********************//
		app_btn_config_t btn_conf;
		btn_conf.config = m_button_cfg;
		btn_conf.btn_count = 1;
		btn_conf.get_tick_cb = xTaskGetTickCount;
		btn_conf.btn_initialize = button_initialize;
		btn_conf.btn_read = btn_read;
		btn_conf.scan_interval_ms = 50;
		app_btn_initialize(&btn_conf);
		//    app_btn_initialize(&btn_conf);
		app_btn_register_callback(APP_BTN_EVT_HOLD, on_btn_hold, NULL);
		app_btn_register_callback(APP_BTN_EVT_HOLD_SO_LONG, on_btn_hold_so_long, NULL);
		app_btn_register_callback(APP_BTN_EVT_PRESSED, on_btn_pressed, NULL);
		app_btn_register_callback(APP_BTN_EVT_RELEASED, on_btn_release, NULL);

		m_button_event_group = xEventGroupCreate(); //>>>>>>> CREATE BUTTON EVENT VAR

//************************* INIT BUTTON END **********************//
		 m_wdg_event_group = xEventGroupCreate();	  // creat group of wdt

		HAL_ADC_Start_DMA (&hadc1, (uint32_t*)ADCScan, 2); //>>>Start ADC
		vTaskDelay(500);
  /* Infinite loop */

		 httpQueue = xQueueCreate (1, sizeof(uint32_t));
#if LWIP_DHCP
	  /* Start DHCPClient */
	  osThreadDef(DHCP, DHCP_Thread, osPriorityBelowNormal, 0, configMINIMAL_STACK_SIZE * 2);
	  DHCP_id = osThreadCreate (osThread(DHCP), &g_netif);
#endif
	  if (m_USB_handle == NULL)
	  {
		  xTaskCreate(usb_task, "usb_task", 512, NULL, 4, &m_USB_handle);// pio =1
	  }
	  if (mTest_Handle_t == NULL)
	  {
		  xTaskCreate (testing_task, "testing_task", 1024, NULL, 5, &mTest_Handle_t);
	  }
	  osDelay (200);
	  initialize_stnp();
  for(;;)
  {
	  app_btn_scan(NULL);
//	  if(HAL_GPIO_ReadPin (MODE1_GPIO_Port, MODE1_Pin))
//	  {
//		  DEBUG_INFO ("NOW MODE 1 IS 1\r\n");
//	  }
//	  else
//	  {
//		  DEBUG_INFO ("NOW MODE 1 IS 0\r\n");
//	  }
//	  if(HAL_GPIO_ReadPin (MODE2_GPIO_Port, MODE2_Pin))
//	  	  {
//	  		  DEBUG_INFO ("NOW MODE 2 IS 1\r\n");
//	  	  }
//	  	  else
//	  	  {
//	  		  DEBUG_INFO ("NOW MODE 2 IS 0\r\n");
//	  	  }
    osDelay(100);
  }
  /* USER CODE END StartDefaultTask */
}

/* USER CODE BEGIN Application */
//***************************** USB MSC AND CDC TASK***************************************************************//
static bool m_cdc_debug_register = false;
static lwrb_t m_ringbuffer_usb_cdc_tx;
static uint8_t m_lwrb_tx_raw_buffer[USB_CDC_TX_RING_BUFFER_SIZE];
void tusb_read_callback (void)
{
//	while (1)
//	{
//		uint8_t usb_ch;
//		uint32_t count = tud_cdc_read(&usb_ch, 1);
//		if (count)
//		{
//	//				DEBUG_WARN ("THERE IS DATA FROM USB \r\n");
//	//		lwrb_write (&m_ringbuffer_cli_rx, &usb_ch, 1);
//			app_cli_poll(usb_ch);
//		}
//		else
//		{
//			break;
//		}
//	}
	return;
}
uint32_t cdc_tx(const void *buffer, uint32_t size)
{
	lwrb_write(&m_ringbuffer_usb_cdc_tx, buffer, size);
	return size;
}
void usb_task (void* params)
{
	DEBUG_INFO ("USB TASK\r\n");
	tusb_init_flag = tusb_init ();
	// Create CDC task
	(void) xTaskCreateStatic(cdc_task, "cdc", 256, NULL, 1, cdc_stack, &cdc_taskdef);// pio =2

	while (1)
	{
		tud_task();
	}
}

void cdc_task(void* params)
{
	DEBUG_INFO("ENTER CDC TASK\r\n");
	lwrb_init(&m_ringbuffer_usb_cdc_tx, m_lwrb_tx_raw_buffer, USB_CDC_TX_RING_BUFFER_SIZE);
	for (;;)
	{
//	    // connected() check for DTR bit
//	    // Most but not all terminal client set this when making connection
//		tusb_read_callback();
		if (tud_cdc_connected())
		{
			if (m_cdc_debug_register == false)
			{
				m_cdc_debug_register = true;
				app_debug_register_callback_print(cdc_tx);
			}
			if (tud_cdc_available())
			{
				tusb_read_callback();
			}
		}
		else
		{
			if (m_cdc_debug_register)
			{
				m_cdc_debug_register = false;
				app_debug_unregister_callback_print(cdc_tx);
				// Flush all cdc tx buffer
				char tmp[1];
				while (lwrb_read(&m_ringbuffer_usb_cdc_tx, tmp, 1))
				{

				}
			}
		}

		char buffer[ (TUD_OPT_HIGH_SPEED ? 512 : 64)];
		uint32_t size;
		while (1)
		{
			uint32_t avai = tud_cdc_write_available();
			if (avai >= sizeof(buffer))
			{
				avai = sizeof(buffer);
			}
			size = lwrb_read(&m_ringbuffer_usb_cdc_tx, buffer, avai);
			if (size)
			{
				tud_cdc_write(buffer, size);
				tud_cdc_write_flush();
			}
			else
			{
				break;
			}
		}
		xEventGroupSetBits(m_wdg_event_group, cdcTaskB);
		vTaskDelay(pdMS_TO_TICKS(1));
	}
}
//*************************************************************************************************************************/

//*****************************************  ETHERNET TASKING ***********************************************************//
void Netif_Config (bool restart)
{
	ip4_addr_t ipaddr;
	ip4_addr_t netmask;
	ip4_addr_t gw;
	  /* IP addresses initialization with DHCP (IPv4) */
	  ipaddr.addr = 0;
	  netmask.addr = 0;
	  gw.addr = 0;
	  if (restart)
	  {
			netif_remove (&g_netif);
			DEBUG_INFO ("NET IF REMOVE \r\n");
	  /* Start DHCP negotiation for a network interface (IPv4) */

	  }
	  /* add the network interface (IPv4/IPv6) with RTOS */
	  netif_add(&g_netif, &ipaddr, &netmask, &gw, NULL, &ethernetif_init, &tcpip_input);//&tcpip_input =>null

	  /* Registers the default network interface */
	  netif_set_default(&g_netif);
	  netif_set_link_callback(&g_netif, ethernet_link_status_updated);
	  if (netif_is_link_up(&g_netif))
	  {
	    /* When the netif is fully configured this function must be called */
	    netif_set_up(&g_netif);
	  }
	  else
	  {
	    /* When the netif link is down this function must be called */
	    netif_set_down(&g_netif);
	  }
	  app_ethernet_notification(&g_netif);
	  /* Set the link callback function, this function is called on change of link status*/

	  DEBUG_INFO ("SET LINK CALLBACK \r\n");

}

//***************************************************************************************************//

//************************** NET APP TASK ***************************************************************//
FRESULT fre;  // result
DIR dir;
void net_task(void *argument)
{
	DEBUG_INFO("ENTER THE HTTP AND MQTT TASK\r\n");
//	xSemaphoreTake(hHttpStart, portMAX_DELAY);
//	DEBUG_INFO ("PASS SEM TAKE \r\n");
//	m_http_test_started = true;
//	while (!m_ip_assigned)
//		 {
//			 vTaskDelay(10);
//		 }
//	  initialize_stnp();
//	  osDelay (1);
//	DEBUG_WARN ("GOT IP START TO SEND!!!!!!!!!!!!!!!!!!!!!!!!!!!!!!!!!!!!!!\r\n");
	// http://httpbin.org/get

	jig_value_t* rev_jig_value;
	app_http_config_t http_cfg;
	app_http_config_t http_cfg_file;
	uint32_t len;
	ETHERNET_STATE e_state = NOT_CONNECTED;
	char file_name [64];
	sent_an_offline_file = xSemaphoreCreateBinary ();
	for (;;)
	{
		switch (e_state)
		{
		case NOT_CONNECTED:
			if (m_ip_assigned) e_state = CONNECT;
			break;
		case CONNECT:
			if (fatfs_check_file ("offline_test") == 1)
			{
				fre = fatfs_create_a_dir ("offline_test");
			}

			RTC_DateTypeDef sDateReadFile = {0};
			HAL_RTC_GetDate (&hrtc, &sDateReadFile, RTC_FORMAT_BIN);
			uint8_t this_month = sDateReadFile.Month;
			uint8_t last_month;
			uint8_t year = sDateReadFile.Year;
			if (this_month == 1)
			{
				last_month = 12;
				year = year - 1;
			}
			else
			{
				last_month = this_month - 1;
			}
			uint8_t month_read = day_in_month[this_month + 1];
			uint8_t last_month_read = day_in_month[last_month + 1];
//			sprintf (file_name, "offline_test/test%d-%d-%d", sDateWriteFile.Date, sDateWriteFile.Month, sDateWriteFile.Year);
			//scan file sequence
			for (uint8_t i = 1; i < last_month_read; i++)
			{
				sprintf (file_name, "0:/offline_test/test%d-%d-%d", i, last_month, year);
				if(!fatfs_check_file (file_name))
				{
					len = fatfs_read_file (file_name, (uint8_t *)json_send_to_sever, 1024);
					DEBUG_INFO ("READ %u byte \r\n", len);
					if (len)
					{
						DEBUG_INFO ("json from file: %s\r\n", json_send_to_sever);
						sprintf(http_cfg_file.url, "%s", "dev-api.basato.vn");
						http_cfg.port = 80;
						sprintf(http_cfg_file.file, "%s", "/fact/api/firesafe/test-result");
						http_cfg_file.on_event_cb = (void*)0;
						http_cfg_file.method = APP_HTTP_POST;
						http_cfg_file.transfile = TRANS_FILE;
						trans_file_name_to_make_body (file_name);
						app_http_start(&http_cfg_file,  (int)len);
//						delete_a_file (file_name);
//						DEBUG_INFO ("SEND OFFLINE FILE\r\n");
					}
					if (xSemaphoreTake (sent_an_offline_file, 15000) == pdTRUE)
					{
						DEBUG_INFO("Delete file %s\r\n", file_name);
						fatfs_delete_a_file (file_name);
					}
				}
			}
			for (uint8_t i = 1; i <= month_read; i++)
			{
				sprintf (file_name, "0:/offline_test/test%d-%d-%d", i, sDateReadFile.Month, sDateReadFile.Year);
				if(!fatfs_check_file (file_name))
				{
//					len = fatfs_read_file (file_name, (uint8_t *)json_send_to_sever, 1024);
//					DEBUG_INFO ("READ %u byte \r\n", len);
					len = fatfs_get_file_size (file_name);
					DEBUG_INFO ("FILE SIZE : %d \r\n", len);
					if (len)
					{
//						DEBUG_INFO ("json from file: %s\r\n", json_send_to_sever);
						sprintf(http_cfg_file.url, "%s", "192.168.1.28");
						http_cfg_file.port = 80;
						sprintf(http_cfg_file.file, "%s", "/test.txt");
						http_cfg_file.on_event_cb = (void*)0;
						http_cfg_file.method = APP_HTTP_POST;
						http_cfg_file.transfile = TRANS_FILE;
						trans_file_name_to_make_body (file_name);
						app_http_start(&http_cfg_file,  (int)len);
//						send_offline_file = true;
					}
					if (xSemaphoreTake (sent_an_offline_file, 15000) == pdTRUE)
					{
						DEBUG_INFO("Delete file %s\r\n", file_name);
						fatfs_delete_a_file (file_name);
//						}
					}
				}
			}

//			if(!check_file ("offline_file"))
//			{
//				len = fatfs_read_file ("offline_file", (uint8_t *)json_send_to_sever, 1024);
//				if (len)
//				{
//					DEBUG_INFO ("json from file: %s\r\n", json_send_to_sever);
//					sprintf(http_cfg.url, "%s", "dev-api.basato.vn");
//					http_cfg.port = 80;
//					sprintf(http_cfg.file, "%s", "/fact/api/firesafe/test-result");
//					http_cfg.on_event_cb = (void*)0;
//					http_cfg.method = APP_HTTP_POST;
//					trans_content_to_body ((uint8_t *) json_send_to_sever, len);
//					DEBUG_INFO ("SEND");
//					app_http_start(&http_cfg,  (int)len);
//					delete_a_file ("offline_file");
//					DEBUG_INFO ("SEND OFFLINE FILE\r\n");
//				}
//			}
			e_state = ETHERNET_CONNECTED;
			break;
		case ETHERNET_CONNECTED:
			if (!eth_is_cable_connected (&g_netif) )
			{
				e_state = NOT_CONNECTED;
				m_ip_assigned = false;
			}
//			if (send_offline_file)
//			{
//				for (uint8_t i = 1; i < month_read; i++)
//				{
//					sprintf (file_name, "0:/offline_test/test%d-%d-%d", i, sDateReadFile.Month, sDateReadFile.Year);
//					if(!check_file (file_name))
//					{
//						delete_a_file (file_name);
//					}
//				}
//				send_offline_file = false;
//			}
			break;
		default:
			break;
		}
		if (xQueueReceive(httpQueue, &rev_jig_value, 10) == (BaseType_t)1)
		{
			len = json_build (rev_jig_value, &(rev_jig_value->test_result), json_send_to_sever);
			vPortFree(rev_jig_value);
			DEBUG_INFO ("RECIEVE QUEUE AND FREE PTR NOW \r\n");
			DEBUG_INFO ("%s\r\n",json_send_to_sever);
			if (eth_is_cable_connected (&g_netif) )
			{
				sprintf(http_cfg.url, "%s", "192.168.1.28");
				http_cfg.port = 80;
				sprintf(http_cfg.file, "%s", "/test.txt");
				http_cfg.on_event_cb = (void*)0;
				http_cfg.method = APP_HTTP_POST;
				http_cfg.transfile = TRANS_STRING;
				trans_content_to_body ((uint8_t *) json_send_to_sever, len);
				app_http_start(&http_cfg,  (int)len);
			}
			else
			{
				if (check_file ("offline_test") == 1)
				{
					fatfs_create_a_dir ("offline_test");
				}
				{
				DIR dir;
//				UINT i;
				fre = f_opendir(&dir, "offline_test");
				if (fre == FR_OK)
				{
					RTC_DateTypeDef sDateWriteFile = {0};
					HAL_RTC_GetDate (&hrtc, &sDateWriteFile, RTC_FORMAT_BIN);
					sprintf (file_name, "offline_test/test%d-%d-%d", sDateWriteFile.Date, sDateWriteFile.Month, sDateWriteFile.Year);
					uint32_t byte = fatfs_get_file_size (file_name);
					DEBUG_INFO ("NOW HAVE %u BYTE\r\n", byte);
					uint32_t byte_write = fatfs_write_json_to_a_file_at_pos (file_name, json_send_to_sever, (uint32_t)len, byte);

					if (byte_write == len)
					{
						DEBUG_INFO ("WRITE FILE OK \r\n");
					}
					else
					{
						DEBUG_ERROR ("WRITE FILE ERROR \r\n");
					}

					f_closedir(&dir);
				}
				}
//				uint32_t byte_write = fatfs_write_to_a_file ("offline_file", json_send_to_sever, (uint32_t)len);
//				if (byte_write == len)
//				{
//					DEBUG_INFO ("WRITE FILE OK \r\n");
//				}
//				else
//				{
//					DEBUG_ERROR ("WRITE FILE ERROR \r\n");
//				}
			}
			xEventGroupSetBits(m_wdg_event_group, netTaskB);
		}
		else
		{
			xEventGroupSetBits(m_wdg_event_group, netTaskB);
		}
		osDelay (10);
	}
}
//***********************************************************************************************************//

//*********************************** TEST TASK******************************************************//
static uint32_t start_time = 0;
static bool start_testing = false;
void testing_task (void *arg)
{
	//init min protocol
	lwrb_init (&m_ringbuffer_rs485_rx, &rs485ringBuffer, sizeof (rs485ringBuffer));
	lwrb_init (&m_ringbuffer_host_rx, &m_rs232_host_buffer, sizeof (m_rs232_host_buffer));
	m_min_setting.get_ms = sys_get_ms;
	m_min_setting.last_rx_time = 0x00;
	m_min_setting.rx_callback = min_rx_callback;
	m_min_setting.timeout_not_seen_rx = 5000;
	m_min_setting.tx_byte = RS232_tx;
	m_min_setting.use_timeout_method = 1;

	m_min_context.callback = &m_min_setting;
	m_min_context.rx_frame_payload_buf = m_min_rx_buffer;
	min_init_context(&m_min_context);
	uint32_t last_tick = 0;
	uint32_t last_tick_time_out = 0;
	uint32_t last_vol_tick = 0;
//	uint32_t json_len;
	//************** INIT GPIO TO TEST****************//
	HAL_GPIO_DeInit (GPIOB, GPIO_PIN_12|GPIO_PIN_13|GPIO_PIN_14|GPIO_PIN_15);
	HAL_GPIO_DeInit (GPIOC, ESP_IO0_Pin|ESP_EN_Pin );
	HAL_GPIO_DeInit (GPIOA, GD32_SDIO_Pin|GD32_CLK_Pin );
	GPIO_InitTypeDef GPIO_InitStruct1 = {0};
	GPIO_InitStruct1.Pin = ESP_IO0_Pin|ESP_EN_Pin ;
	GPIO_InitStruct1.Mode = GPIO_MODE_ANALOG;
	GPIO_InitStruct1.Pull = GPIO_NOPULL;
	HAL_GPIO_Init(GPIOC, &GPIO_InitStruct1);
	HAL_GPIO_WritePin(GPIOC, ESP_IO0_Pin|ESP_EN_Pin, GPIO_PIN_SET);
	GPIO_InitTypeDef GPIO_InitStruct2 = {0};
	GPIO_InitStruct2.Pin = GPIO_PIN_12|GPIO_PIN_13|GPIO_PIN_14|GPIO_PIN_15;
	GPIO_InitStruct2.Mode = GPIO_MODE_ANALOG;
	GPIO_InitStruct2.Pull = GPIO_NOPULL;
	HAL_GPIO_Init(GPIOB, &GPIO_InitStruct2);
	GPIO_InitTypeDef GPIO_InitStruct3 = {0};
	GPIO_InitStruct3.Pin = GD32_SDIO_Pin|GD32_CLK_Pin;
	GPIO_InitStruct3.Mode = GPIO_MODE_ANALOG;
	GPIO_InitStruct3.Pull = GPIO_NOPULL;
	HAL_GPIO_Init(GPIOA, &GPIO_InitStruct3);

	//***********************************************//
	const min_msg_t test_cmd =
	{
			.id = MIN_ID_RS232_ENTER_TEST_MODE,
			.len = 0,
			.payload = NULL
	};
	const min_msg_t reset_cmd_wd =
	{
			.id = MIN_ID_TEST_WATCHDOG,
			.len = 0,
			.payload = NULL
	};
	if (m_disk_is_mounted)
	{
		DEBUG_VERBOSE ("READ VOLTAGE CONFIG FILE\r\n");
		uint32_t file_size = fatfs_read_file(test_info_file, (uint8_t*)V_info_buff, sizeof(V_info_buff) - 1);
		/*
		 * {vbatmax:4.3,
		 * 	vbatmin:4.5,
		 *
		 *
		 * }
		 * */
		DEBUG_VERBOSE ("READ %d byte size\r\n", file_size);
		DEBUG_INFO ("%s", V_info_buff);
		if (file_size > 0)
		{
			char *ptr = strstr((char*)V_info_buff, "\"vbat_max\":");
			if (ptr)
			{
				ptr+=strlen("\"vbat_max\":");
				voltage_info.vbat_max = utilities_get_number_from_string (0, ptr);
			}
			ptr = strstr((char*)V_info_buff,"\"vbat_min\":");
			if (ptr)
			{
				ptr+=strlen("\"vbat_min\":");
				voltage_info.vbat_min = utilities_get_number_from_string (0, ptr);
			}
			ptr = strstr((char*)V_info_buff, "\"v1v8_max\":");
			if (ptr)
			{
				ptr+=strlen("\"v1v8_max\":");
				voltage_info.v1v8_max = utilities_get_number_from_string (0, ptr);
			}
			ptr = strstr((char*)V_info_buff, "\"v1v8_min\":");
			if (ptr)
			{
				ptr+=strlen("\"v1v8_min\":");
				voltage_info.v1v8_min = utilities_get_number_from_string (0, ptr);
			}
			ptr = strstr((char*)V_info_buff, "\"v3v3_max\":");
			if (ptr)
			{
				ptr+=strlen("\"v3v3_max\":");
				voltage_info.v3v3_max = utilities_get_number_from_string (0, ptr);
			}
			ptr = strstr((char*)V_info_buff, "\"v3v3_min\":");
			if (ptr)
			{
				ptr+=strlen("\"v3v3_min\":");
				voltage_info.v3v3_min = utilities_get_number_from_string (0, ptr);
			}
//			ptr = strstr((char*)V_info_buff, "\"v5v_max\":");
//			if (ptr)
//			{
//				ptr+=strlen("\"v5v_max\":");
//				voltage_info.v5v_max = utilities_get_number_from_string (0, ptr);
//			}
//			ptr = strstr((char*)V_info_buff, "\"v5v_min\":");
//			if (ptr)
//			{
//				ptr+=strlen("\"v5v_min\":");
//				voltage_info.v5v_min = utilities_get_number_from_string (0, ptr);
//			}
//			ptr = strstr((char*)V_info_buff, "\"v4v2_max\":");
//			if (ptr)
//			{
//				ptr+=strlen("\"v4v2_max\":");
//				voltage_info.v4v2_max = utilities_get_number_from_string (0, ptr);
//			}
//			ptr = strstr((char*)V_info_buff, "\"v4v2_min\":");
//			if (ptr)
//			{
//				ptr+=strlen("\"v4v2_min\":");
//				voltage_info.v4v2_min = utilities_get_number_from_string (0, ptr);
//			}
			ptr = strstr((char*)V_info_buff, "\"vsys_max\":");
			if (ptr)
			{
				ptr+=strlen("\"vsys_max\":");
				voltage_info.vsys_max = utilities_get_number_from_string (0, ptr);
			}
			ptr = strstr((char*)V_info_buff, "\"vsys_min\":");
			if (ptr)
			{
				ptr+=strlen("\"vsys_min\":");
				voltage_info.vsys_min = utilities_get_number_from_string (0, ptr);
			}
#warning "viet them ham tim ten va mat khau wifi"
			DEBUG_INFO ("%d < vbat < %d (mV) \r\n", voltage_info.vbat_min, voltage_info.vbat_max);
//			DEBUG_INFO ("%d < v5v < %d (mV) \r\n", voltage_info.v5v_min, voltage_info.v5v_max);
			DEBUG_INFO ("%d < v1v8 < %d (mV) \r\n", voltage_info.v1v8_min, voltage_info.v1v8_max);
			DEBUG_INFO ("%d < v3v3 < %d (mV) \r\n", voltage_info.v3v3_min, voltage_info.v3v3_max);
//			DEBUG_INFO ("%d < v4v2 < %d (mV) \r\n", voltage_info.v4v2_min, voltage_info.v4v2_max);
			DEBUG_INFO ("%d < vsys < %d (mV) \r\n", voltage_info.vsys_min, voltage_info.vsys_max);
		}
	}
	bool sent_to_sever =false;
//	send_test_command (&test_cmd);
	for (;;)
	{
//		DEBUG_INFO ("ENTER TESTING LOOP \r\n");
		if (HAL_GPIO_ReadPin(MODE1_GPIO_Port, MODE1_Pin))//xet trang thai bit gat
		{
			if (xEventGroupWaitBits(m_button_event_group,
					BIT_EVENT_GROUP_BT_IN_PRESSED,
					pdTRUE,
					pdFALSE,
					0))
			{
				start_testing = true;
				start_time = HAL_GetTick ();
			}
			uint32_t now = HAL_GetTick();
			uint8_t ch;
			if (((now - start_time) >= 60000) && start_testing)
			{
				start_testing = false;
				ready_send_to_sever = true;
				start_time = HAL_GetTick ();
			}

			if (lwrb_read(&m_ringbuffer_host_rx, &ch, 1))
			{
				min_rx_feed(&m_min_context, &ch, 1);
			}
			else
			{

				min_timeout_poll(&m_min_context);
			}

			if(idle_detect)
			{
				idle_detect --;
				if (idle_detect == 0)
				{
//					DEBUG_INFO ("RS485 SAY:\r\n %s", rs485ringBuffer);
					char * testptr = strstr((char*)rs485ringBuffer, "[I]");
					if (testptr)
					{
						test_res.result.rs485 = true;

					}
				}
			}
			if (get_jig_info)
			{
					DEBUG_INFO ("GET EOF START CHECK MAC \r\n");
					if (strcmp((char*)MAC, (char*)lastMAC) != 0 )
					{
						ready_send_to_sever = false;
						sent_to_sever =false;
						test_res.result.rs485 = 0;
						relay_toggle_0 = 0;
						relay_toggle_1 = 0;
						allPassed = 0;
						test_res.result.relay0_ok = 0;
						test_res.result.relay1_ok = 0;
						DEBUG_INFO ("MAC CHANGED: %02x: %02x: %02x: %02x: %02x: %02x\r\n", MAC[0], MAC[1], MAC[2], MAC[3], MAC[4],MAC[5]);
						to_send_value = rx_value;
						if (((to_send_value ->peripheral.value) == 0xFFFF) && (test_res.result.test_wd_ok != 1))
						{
							send_test_command ((min_msg_t *)&reset_cmd_wd);
						}
					}
					else
					{

						DEBUG_WARN ("MAC STILL THE SAME, UPDATE \r\n");
						if (allPassed)
						{
							break;
						}
						if (rx_value ->temperature)
						{
							to_send_value ->temperature = rx_value ->temperature;
						}
						if (rx_value->peripheral.name.eth != 1)
						{
							to_send_value->peripheral.name.eth = rx_value ->peripheral.name.eth;
						}
						if (rx_value ->peripheral.name.wifi  != 1)
						{
							to_send_value ->peripheral.name.wifi  = rx_value ->peripheral.name.wifi ;
						}
						if (rx_value ->peripheral.name.gsm  != 1)
						{
							to_send_value ->peripheral.name.gsm  = rx_value ->peripheral.name.gsm ;
						}
						if (rx_value ->peripheral.name.server  != 1)
						{
							to_send_value ->peripheral.name.server  = rx_value ->peripheral.name.server ;
						}
						if (rx_value ->peripheral.name.input0_pass  != 1)
						{
							to_send_value ->peripheral.name.input0_pass  = rx_value ->peripheral.name.input0_pass ;
						}
						if (rx_value ->peripheral.name.input1_pass  != 1)
						{
							to_send_value ->peripheral.name.input1_pass  = rx_value ->peripheral.name.input1_pass ;
						}
						if (rx_value ->peripheral.name.input2_pass  != 1)
						{
							to_send_value ->peripheral.name.input2_pass  = rx_value ->peripheral.name.input2_pass ;
						}
						if (rx_value ->peripheral.name.input3_pass  != 1)
						{
							to_send_value ->peripheral.name.input3_pass  = rx_value ->peripheral.name.input3_pass ;
						}
						if (rx_value ->peripheral.name.button_pass   != 1)
						{
							to_send_value ->peripheral.name.button_pass   = rx_value ->peripheral.name.button_pass  ;
						}
						if (rx_value ->peripheral.name.main_power_pass   != 1)
						{
							to_send_value ->peripheral.name.main_power_pass   = rx_value ->peripheral.name.main_power_pass  ;
						}
						if (rx_value ->peripheral.name.backup_power_pass   != 1)
						{
							to_send_value ->peripheral.name.backup_power_pass   = rx_value ->peripheral.name.backup_power_pass  ;
						}

						if (((to_send_value ->peripheral.value) == 0xFFFF) && (test_res.result.test_wd_ok != 1))
						{
							send_test_command ((min_msg_t *)&reset_cmd_wd);
						}
						if (PassTest(to_send_value))
						{

							ready_send_to_sever = true;
							sent_to_sever = false;
							DEBUG_INFO ("NOW PASSED SEND AGAIN \r\n");
						}
					}
					for (uint8_t i = 0; i < 6; i++)
					{
						lastMAC[i] = MAC[i];
					}
				if (PassTest(to_send_value))
				{
					DEBUG_INFO ("PASSED ALL TESTS \r\n");
//					json_len = json_build (to_send_value, &test_res, json_send_to_sever);
					ready_send_to_sever = true;
				}
				else
				{
					if ((now - last_tick_time_out) > TIMEOUT)
					{
//						send_json_to_sever();// ban bang queue
//						json_len = json_build (to_send_value, &test_res, json_send_to_sever);
//						DEBUG_INFO ("JSON STRING: %s\r\n", json_send_to_sever);
						DEBUG_INFO ("TIME OUT PREPARE TO SEND \r\n");
						ready_send_to_sever = true;
						last_tick_time_out = now;

					}
				}
				get_jig_info = false;
			}
//			else
//			{
//				if ((now - last_tick_time_out) > TIMEOUT)
//				{
////						send_json_to_sever();// ban bang queue
////						json_len = json_build (to_send_value, &test_res, json_send_to_sever);
////						DEBUG_INFO ("JSON STRING: %s\r\n", json_send_to_sever);
//					DEBUG_INFO ("TIME OUT PREPARE TO SEND \r\n");
//					test_res.result.rs232 = 0;
//					ready_send_to_sever = true;
//					last_tick_time_out = now;
//
//				}
//			}

			if (ready_send_to_sever && (sent_to_sever == false))
			{
				date_time_t date_time_buff;
				sent_to_sever = true;
				jig_value_t* buff_jig_var;
				buff_jig_var = (jig_value_t *) pvPortMalloc(sizeof (jig_value_t));

				HAL_RTC_GetTime (&hrtc, &sTimeToSend, RTC_FORMAT_BIN);
				HAL_RTC_GetDate (&hrtc, &sDateToSend, RTC_FORMAT_BIN);
				date_time_buff.day = sDateToSend.Date;
				date_time_buff.month = sDateToSend.Month;
				date_time_buff.year = sDateToSend.Year;
				date_time_buff.hour = sTimeToSend.Hours - 7;
				date_time_buff.minute = sTimeToSend.Minutes;
				date_time_buff.second = sTimeToSend.Seconds;
				buff_jig_var->timestamp = convert_date_time_to_second (&date_time_buff);
				buff_jig_var->timestamp += 946684800; // add time from 1970 to 2000
				DEBUG_INFO ("GET TIME: %d: %d: %d \r\n", (uint8_t)(sTimeToSend.Hours), (uint8_t)(sTimeToSend.Minutes),(uint8_t)(sTimeToSend.Seconds));
				DEBUG_INFO ("GET date: %d: %d: %d \r\n", (uint8_t)(sDateToSend.Date), (uint8_t)(sDateToSend.Month),(uint8_t)(sDateToSend.Year));
				DEBUG_WARN ("CALCULATED TIME : %u\r\n", buff_jig_var->timestamp);

				buff_jig_var->device_type = to_send_value->device_type;
				memcpy (buff_jig_var->fw_version, to_send_value->fw_version, 3);
				memcpy (buff_jig_var->hw_version, to_send_value->hw_version, 3);
				memcpy (buff_jig_var->gsm_imei, to_send_value->gsm_imei, 16);
				memcpy (buff_jig_var->mac, to_send_value->mac, 6);
				memcpy (buff_jig_var->sim_imei, to_send_value->sim_imei, 16);
				buff_jig_var->peripheral.value = to_send_value->peripheral.value;
				buff_jig_var->test_result.value = test_res.value;
				buff_jig_var->led_result.led_res = led_detect.led_res;
//				xQueueSend (httpQueue, &buff_jig_var, 0);
				DEBUG_WARN ("SEND queue \r\n");
			}
			if ((now - last_tick) > 500 )
			{
//				DEBUG_INFO ("SEND TEST CMD \r\n");
				send_test_command (&test_cmd);
				last_tick = now;
			}
			if ((now - last_vol_tick) > 1500)
			{
				volTest ();
				last_vol_tick = now;
				check_led_status ();
			}
		}
		else
		{
			DEBUG_VERBOSE ("NOT IN TESTING MODE\r\n");
		}
		osDelay (10);
			uxBits = xEventGroupWaitBits(m_wdg_event_group,
				defaultTaskB | cdcTaskB | usbTaskB | flashTaskB | netTaskB,
										pdTRUE,
										pdTRUE,
										10);

		 if ((uxBits & (defaultTaskB | cdcTaskB  | netTaskB))
			 == (defaultTaskB | cdcTaskB | netTaskB))
		 {
			 HAL_IWDG_Refresh(&hiwdg);
		 }
	}
}
//*********************************************************************************************************************//

void flash_task(void *argument)
{
	DEBUG_INFO("ENTER flash TASK\r\n");
	int32_t file_size = 0;
	 GPIO_InitTypeDef GPIO_InitStruct1 = {0};
	 while (!tusb_init_flag)
	 {
		 vTaskDelay(100);
	 }

	if (m_disk_is_mounted)
	{
//		vTaskDelay (200);
		file_size = fatfs_read_file(info_file, (uint8_t*)m_file_address, sizeof(m_file_address) - 1);
		if (file_size > 0)
		{
			DEBUG_INFO ("READ THE INFO FILE \r\n");
			/*
			{
				"boot":4096,
				"firmware":65536,
				"ota_data":2555904,
				"partition":32768
			}
			*/
			char *ptr = strstr(m_file_address, "\"boot\":");
			if (ptr)
			{
				DEBUG_INFO ("FOUND THE BOOT STRING\r\n");
				ptr += strlen("\"boot\":");
				m_binary.boot.addr = utilities_get_number_from_string(0, ptr);
			}

			ptr = strstr(m_file_address, "\"firmware\":");
			if (ptr)
			{
				ptr += strlen("\"firmware\":");
				m_binary.firm.addr = utilities_get_number_from_string(0, ptr);
			}
			ptr = strstr(m_file_address, "\"ota_data\":");
			if (ptr)
			{
				ptr += strlen("\"ota_data\":");
				m_binary.ota.addr = utilities_get_number_from_string(0, ptr);
			}
			ptr = strstr(m_file_address, "\"partition\":");
			if (ptr)
			{
				ptr += strlen("\"partition\":");
				m_binary.part.addr = utilities_get_number_from_string(0, ptr);
			}
		}

		file_size = fatfs_get_file_size(bootloader_file);
		if (file_size > -1)
		{
			m_binary.boot.size = file_size;
			m_binary.boot.file_name = bootloader_file;
		}

		file_size = fatfs_get_file_size(firmware_file);
		if (file_size > -1)
		{
			m_binary.firm.size = file_size;
			m_binary.firm.file_name = firmware_file;
		}

		file_size = fatfs_get_file_size(ota_file);
		if (file_size > -1)
		{
			m_binary.ota.size = file_size;
			m_binary.ota.file_name = ota_file;
		}

		file_size = fatfs_get_file_size(partition_file);
		if (file_size > -1)
		{
			m_binary.part.size = file_size;
			m_binary.part.file_name = partition_file;
		}

		DEBUG_INFO("Bootloader offset 0x%08X, firmware 0x%08X, ota  0x%08X, partition table 0x%08X\r\n", m_binary.boot.addr, m_binary.firm.addr, m_binary.ota.addr, m_binary.part.addr);
		DEBUG_INFO("Bootloader %u bytes, firmware %u bytes, ota %u bytes, partition table %u bytes\r\n", m_binary.boot.size, m_binary.firm.size, m_binary.ota.size, m_binary.part.size);
	}
	m_loader_cfg.gpio0_trigger_port = (uint32_t)ESP_IO0_GPIO_Port;
	m_loader_cfg.reset_trigger_port = (uint32_t)ESP_EN_GPIO_Port;
	m_loader_cfg.uart_addr = (uint32_t)USART2;
//	m_loader_cfg.spi_addr = (uint32_t)&hspi2;
//	if (m_loader_cfg.spi_addr)
//	{
//		spi_flash_firm_init ((SPI_HandleTypeDef *)m_loader_cfg.spi_addr);
//	}
	esp_loader_error_t err;

	// Clear led busy & success, set led error
//	HAL_GPIO_WritePin(LED_BUSY_GPIO_Port, LED_BUSY_Pin, GPIO_PIN_SET);
//	HAL_GPIO_WritePin(LED_DONE_GPIO_Port, LED_DONE_Pin, GPIO_PIN_SET);

	for (;;)
	{
		if ((HAL_GPIO_ReadPin (MODE1_GPIO_Port, MODE1_Pin) == 0) && (HAL_GPIO_ReadPin (MODE2_GPIO_Port, MODE2_Pin) == 1))
		{
		DEBUG_INFO("ENTER flash LOOP\r\n");
		if (led_busy_toggle > 10)
		{
			led_busy_toggle = 1;
		}
		xEventGroupWaitBits(m_button_event_group,
								BIT_EVENT_GROUP_BT_IN_PRESSED,
								pdTRUE,
								pdFALSE,
								portMAX_DELAY);
		//   THRERE one KEY NOW
		DEBUG_INFO("KEY IS PRESSED\r\n");
		USART2->CR1 |= (uint32_t)(1<<2);
		DEBUG_INFO ("RECIEVE ENABLE \r\n");
		GPIO_InitStruct1.Pin = ESP_EN_Pin|ESP_IO0_Pin;
		GPIO_InitStruct1.Mode = GPIO_MODE_OUTPUT_PP;
		GPIO_InitStruct1.Pull = GPIO_NOPULL;
		GPIO_InitStruct1.Speed = GPIO_SPEED_FREQ_LOW;
		HAL_GPIO_Init(GPIOC, &GPIO_InitStruct1);
		DEBUG_INFO ("REINT IO0 \r\n");
//		HAL_GPIO_WritePin(LED_BUSY_GPIO_Port, LED_BUSY_Pin, GPIO_PIN_RESET);
//		HAL_GPIO_WritePin(LED_ERROR_GPIO_Port, LED_ERROR_Pin, GPIO_PIN_SET);
//		HAL_GPIO_WritePin(LED_DONE_GPIO_Port, LED_DONE_Pin, GPIO_PIN_SET);
		uint32_t now = xTaskGetTickCount();
		uint32_t retry = 4;
		while (m_binary.part.size > 0
				&& m_binary.firm.size > 0
				&& m_binary.ota.size >0
				&& m_binary.part.size > 0
				)
		{
			if (retry == 0)
			{
				break;
			}
			retry--;
			loader_port_change_baudrate(&m_loader_cfg, 115200);
			DEBUG_INFO("Connecting to target remain %u times\r\n", retry);
			led_busy_toggle = 1000000;
			err = esp_loader_connect(&m_loader_cfg);
			if (err != ESP_LOADER_SUCCESS)
			{
				DEBUG_ERROR("Connect to target failed %d\r\n", err);
//				HAL_GPIO_WritePin(LED_ERROR_GPIO_Port, LED_BUSY_Pin, GPIO_PIN_RESET);
				continue;
			}
			else
			{
				DEBUG_INFO("Connected to target %s\r\n", chip_des[m_loader_cfg.target]);
			}
			DEBUG_INFO("Change baudrate\r\n");
			err = esp_loader_change_baudrate(&m_loader_cfg, 115200);
			if (err == ESP_LOADER_ERROR_UNSUPPORTED_FUNC)
			{
				DEBUG_ERROR("ESP8266 does not support change baudrate command\r\n");
			}
			else if (err != ESP_LOADER_SUCCESS)
			{
				DEBUG_ERROR("Unable to change baud rate on target\r\n");
			}
			else
			{
				err = loader_port_change_baudrate(&m_loader_cfg, 115200);
				if (err != ESP_LOADER_SUCCESS)
				{
					DEBUG_ERROR("Unable to change baud rate\r\n");
				}
				else
				{
					DEBUG_INFO("Port[%u] : Baudrate changed\r\n");
				}
			}

			DEBUG_INFO("Flash bootloader\r\n");
			if (flash_binary_stm32(&m_loader_cfg, &m_binary.boot) != ESP_LOADER_SUCCESS)
			{
				DEBUG_INFO("FLASH BOOTLOADER FAIL \r\n");
//				HAL_GPIO_WritePin(LED_ERROR_GPIO_Port, LED_ERROR_Pin, GPIO_PIN_RESET);
				HAL_GPIO_WritePin(BUZZ_GPIO_Port, BUZZ_Pin, GPIO_PIN_SET);
				vTaskDelay(4000);
				HAL_GPIO_WritePin(BUZZ_GPIO_Port, BUZZ_Pin, GPIO_PIN_RESET);
				xEventGroupClearBits(m_button_event_group,
									BIT_EVENT_GROUP_BT_IN_PRESSED);
				break;
			}

			DEBUG_INFO("Flash firm\r\n");
			if (flash_binary_stm32(&m_loader_cfg, &m_binary.firm) != ESP_LOADER_SUCCESS)
			{
				DEBUG_INFO("FLASH firmware FAIL \r\n");
//				HAL_GPIO_WritePin(LED_ERROR_GPIO_Port, LED_ERROR_Pin, GPIO_PIN_RESET);
				HAL_GPIO_WritePin(BUZZ_GPIO_Port, BUZZ_Pin, GPIO_PIN_SET);
				vTaskDelay(4000);
				HAL_GPIO_WritePin(BUZZ_GPIO_Port, BUZZ_Pin, GPIO_PIN_RESET);
				xEventGroupClearBits(m_button_event_group,
									BIT_EVENT_GROUP_BT_IN_PRESSED);
				break;
			}
#warning "Chua nap thanh cong file ota"
//			DEBUG_INFO("Flash ota\r\n");
//			if (flash_binary_stm32(&m_loader_cfg, &m_binary.ota) != ESP_LOADER_SUCCESS)
//			{
//				DEBUG_INFO("FLASH OTA FAIL \r\n");
//				HAL_GPIO_WritePin(LED_ERROR_GPIO_Port, LED_ERROR_Pin, GPIO_PIN_RESET);
//				HAL_GPIO_WritePin(BUZZ_GPIO_Port, BUZZ_Pin, GPIO_PIN_SET);
//				vTaskDelay(4000);
//				HAL_GPIO_WritePin(BUZZ_GPIO_Port, BUZZ_Pin, GPIO_PIN_RESET);
//				xEventGroupClearBits(m_button_event_group,
//									BIT_EVENT_GROUP_KEY_0_PRESSED);
//				break;
//			}

			DEBUG_INFO("Flash partition table\r\n");
			if (flash_binary_stm32(&m_loader_cfg, &m_binary.part) != ESP_LOADER_SUCCESS)
			{
				DEBUG_INFO("FLASH partition FAIL \r\n");
//				HAL_GPIO_WritePin(LED_ERROR_GPIO_Port, LED_ERROR_Pin, GPIO_PIN_RESET);
				HAL_GPIO_WritePin(BUZZ_GPIO_Port, BUZZ_Pin, GPIO_PIN_SET);
				vTaskDelay(4000);
				HAL_GPIO_WritePin(BUZZ_GPIO_Port, BUZZ_Pin, GPIO_PIN_RESET);
				xEventGroupClearBits(m_button_event_group,
									BIT_EVENT_GROUP_BT_IN_PRESSED);

				break;
			}
			retry = 0;
			xEventGroupClearBits(m_button_event_group,
								BIT_EVENT_GROUP_BT_IN_PRESSED);
			DEBUG_INFO ("Total flash write time %us\r\n", (xTaskGetTickCount() - now)/1000);
//			HAL_GPIO_WritePin (LED_ERROR_GPIO_Port, LED_BUSY_Pin, GPIO_PIN_RESET);
//			HAL_GPIO_WritePin (GPIOF, LED_DONE_Pin, GPIO_PIN_RESET);
			if (led_busy_toggle > 10)
			{
				led_busy_toggle = 1;
			}

			loader_port_change_baudrate (&m_loader_cfg, 115200);
			// loader_port_reset_target(&m_loader_cfg);
			// Led success on, led busy off
//			HAL_GPIO_WritePin(LED_DONE_GPIO_Port, LED_DONE_Pin, GPIO_PIN_RESET);
//			HAL_GPIO_WritePin(LED_BUSY_GPIO_Port, LED_BUSY_Pin, GPIO_PIN_SET);

			//// io0 reint
			GPIO_InitStruct1.Pin = ESP_IO0_Pin;
			GPIO_InitStruct1.Mode = GPIO_MODE_ANALOG;
			GPIO_InitStruct1.Pull = GPIO_NOPULL;
			HAL_GPIO_Init(ESP_IO0_GPIO_Port, &GPIO_InitStruct1);
			HAL_GPIO_WritePin((GPIO_TypeDef*)m_loader_cfg.gpio0_trigger_port, m_loader_cfg.gpio0_trigger_pin, GPIO_PIN_SET);
			/// end reint
			DEBUG_INFO ("SET GPIO0 ANALOG MODE \r\n");
			USART2->CR1 &= (uint32_t)(~(1<<2));
			DEBUG_INFO ("RE IS DISABLE \r\n");
			break;
		}
		vTaskDelay(45000);
		DEBUG_INFO ("WAIT 45S DONE \r\n");
		}
		else
		{
//			DEBUG_INFO ("IN FLASH TASK \r\n");
			xEventGroupSetBits(m_wdg_event_group, flashTaskB);
			vTaskDelay(10);
		}
	}
}

//*******************************************************************************************//
void flashbyspi(void)
{
	for (;;)
	{
		if (m_disk_is_mounted)
		{
	//		vTaskDelay (200);
			uint32_t file_size = fatfs_read_file(info_file, (uint8_t*)m_file_address, sizeof(m_file_address) - 1);
			if (file_size > 0)
			{
				DEBUG_INFO ("READ THE INFO FILE \r\n");
				/*
				{
					"boot":4096,
					"firmware":65536,
					"ota_data":2555904,
					"partition":32768
				}
				*/
				char *ptr = strstr(m_file_address, "\"boot\":");
				if (ptr)
				{
					DEBUG_INFO ("FOUND THE BOOT STRING\r\n");
					ptr += strlen("\"boot\":");
					m_binary.boot.addr = utilities_get_number_from_string(0, ptr);
				}

				ptr = strstr(m_file_address, "\"firmware\":");
				if (ptr)
				{
					ptr += strlen("\"firmware\":");
					m_binary.firm.addr = utilities_get_number_from_string(0, ptr);
				}
				ptr = strstr(m_file_address, "\"ota_data\":");
				if (ptr)
				{
					ptr += strlen("\"ota_data\":");
					m_binary.ota.addr = utilities_get_number_from_string(0, ptr);
				}
				ptr = strstr(m_file_address, "\"partition\":");
				if (ptr)
				{
					ptr += strlen("\"partition\":");
					m_binary.part.addr = utilities_get_number_from_string(0, ptr);
				}
			}

			file_size = fatfs_get_file_size(bootloader_file);
			if (file_size > -1)
			{
				m_binary.boot.size = file_size;
				m_binary.boot.file_name = bootloader_file;
			}

			file_size = fatfs_get_file_size(firmware_file);
			if (file_size > -1)
			{
				m_binary.firm.size = file_size;
				m_binary.firm.file_name = firmware_file;
			}

			file_size = fatfs_get_file_size(ota_file);
			if (file_size > -1)
			{
				m_binary.ota.size = file_size;
				m_binary.ota.file_name = ota_file;
			}

			file_size = fatfs_get_file_size(partition_file);
			if (file_size > -1)
			{
				m_binary.part.size = file_size;
				m_binary.part.file_name = partition_file;
			}

			DEBUG_INFO("Bootloader offset 0x%08X, firmware 0x%08X, ota  0x%08X, partition table 0x%08X\r\n", m_binary.boot.addr, m_binary.firm.addr, m_binary.ota.addr, m_binary.part.addr);
			DEBUG_INFO("Bootloader %u bytes, firmware %u bytes, ota %u bytes, partition table %u bytes\r\n", m_binary.boot.size, m_binary.firm.size, m_binary.ota.size, m_binary.part.size);
		}
		m_loader_cfg.gpio0_trigger_port = (uint32_t)ESP_IO0_GPIO_Port;
		m_loader_cfg.reset_trigger_port = (uint32_t)ESP_EN_GPIO_Port;
		static app_flash_drv_t m_spi_flash_firm;
		if (m_loader_cfg.spi_addr)
		{
			m_spi_flash_firm.spi = &hspi2;
			m_spi_flash_firm.callback.spi_cs = app_drv_spi_cs;
			m_spi_flash_firm.callback.spi_rx_buffer = app_drv_spi_receive_frame;
			m_spi_flash_firm.callback.spi_tx_buffer = app_drv_spi_transmit_frame;
			m_spi_flash_firm.callback.spi_tx_rx = app_drv_spi_transmit_receive_frame;
			m_spi_flash_firm.callback.spi_tx_byte = app_drv_spi_transmit_byte;
			m_spi_flash_firm.callback.delay_ms = NULL;
		}
		uint32_t now = xTaskGetTickCount();
		uint32_t retry = 4;
		// set reset pin to 0
		HAL_GPIO_WritePin ((GPIO_TypeDef *)m_loader_cfg.reset_trigger_port, m_loader_cfg.reset_trigger_pin, GPIO_PIN_RESET);
		// init flash size esp
		while (m_binary.part.size > 0
				&& m_binary.firm.size > 0
				&& m_binary.ota.size >0
				&& m_binary.part.size > 0
				)
		{
			if (retry == 0)
			{
				break;
			}
			retry--;
			DEBUG_INFO ("FLASH BOOT FILE BY SPI\r\n");
			app_spi_flash_erase_sector_4k (&m_spi_flash_firm, (uint32_t)(m_binary.boot.addr/APP_SPI_FLASH_SECTOR_SIZE));
			m_binary.boot.data = (uint8_t *)pvPortMalloc (m_binary.boot.size * sizeof(uint8_t));
			app_spi_flash_write (&m_spi_flash_firm, m_binary.boot.addr, m_binary.boot.data, m_binary.boot.size);
			vPortFree ((uint8_t *)m_binary.boot.data);
			DEBUG_INFO ("FLASHED BOOT FILE\r\n");
			DEBUG_INFO ("FLASH FIRMWARE FILE BY SPI\r\n");
			app_spi_flash_erase_sector_4k (&m_spi_flash_firm, (uint32_t)(m_binary.firm.addr/APP_SPI_FLASH_SECTOR_SIZE));
			m_binary.firm.data = (uint8_t *)pvPortMalloc (m_binary.firm.size * sizeof(uint8_t));
			app_spi_flash_write (&m_spi_flash_firm, m_binary.firm.addr, m_binary.firm.data, m_binary.firm.size);
			vPortFree ((uint8_t *)m_binary.firm.data);
			DEBUG_INFO ("FLASHED FIRMWARE FILE \r\n");
			DEBUG_INFO ("FLASH OTA FILE BY SPI\r\n");
			app_spi_flash_erase_sector_4k (&m_spi_flash_firm, (uint32_t)(m_binary.ota.addr/APP_SPI_FLASH_SECTOR_SIZE));
			m_binary.ota.data = (uint8_t *)pvPortMalloc (m_binary.ota.size * sizeof(uint8_t));
			app_spi_flash_write (&m_spi_flash_firm, m_binary.ota.addr, m_binary.ota.data, m_binary.ota.size);
			vPortFree ((uint8_t *)m_binary.ota.data);
			DEBUG_INFO ("FLASHED OTA FILE \r\n");
			DEBUG_INFO ("FLASH OTA FILE BY SPI\r\n");
			app_spi_flash_erase_sector_4k (&m_spi_flash_firm, (uint32_t)(m_binary.part.addr/APP_SPI_FLASH_SECTOR_SIZE));
			m_binary.part.data = (uint8_t *)pvPortMalloc (m_binary.part.size * sizeof(uint8_t));
			app_spi_flash_write (&m_spi_flash_firm, m_binary.part.addr, m_binary.part.data, m_binary.part.size);
			vPortFree ((uint8_t *)m_binary.part.data);
			DEBUG_INFO ("FLASHED OTA FILE \r\n");

		}

	}
}

// *********************** interrupt callback ************************//
void rs232_rx_callback (void)
{
	uint8_t ch = getChar (UART5);
	lwrb_write (&m_ringbuffer_host_rx, &ch, 1);
}

void rs485_rx_callback (void)
{
	idle_detect = 5;
	uint8_t ch =getChar(USART3);
	lwrb_write (&m_ringbuffer_rs485_rx, &ch, 1);
//	DEBUG_ISR ("%c",ch);
}

void HAL_GPIO_EXTI_Callback(uint16_t GPIO_Pin)
{
  /* Prevent unused argument(s) compilation warning */
  UNUSED(GPIO_Pin);
  /* NOTE: This function Should not be modified, when the callback is needed,
           the HAL_GPIO_EXTI_Callback could be implemented in the user file
   */
  if (GPIO_Pin == RELAY_NO_Pin)
  {
	  relay_toggle_0 ++;
	  if (relay_toggle_0 > 5)
	  {
		  test_res.result.relay0_ok = 1;
		  relay_toggle_0 = 0;
	  }
  }
  else if (GPIO_Pin == RELAY_NC_Pin)
  {
	  relay_toggle_0 ++;
	  if (relay_toggle_1 > 5)
	  {
		  relay_toggle_1 = 0;
		  test_res.result.relay1_ok = 1;
	  }
  }
}
//********************************************************************//

//*******************************************************************************************************//
//										FUNCTION USE													//
//*****************************************************************************************************//

void send_test_command(min_msg_t * test_command)
{
	min_send_frame (&m_min_context, test_command);
}
void Get_MAC(jig_value_t * value, uint8_t *MAC)
{
	for (uint8_t i = 0 ; i < 6; i++)
	{
		MAC[i] = value ->mac[i];
	}
}

void min_rx_callback (void *min_context , min_msg_t *frame)
{
	switch (frame ->id)
	{
	case MIN_ID_RS232_ENTER_TEST_MODE:
		rx_value = (jig_value_t *)frame->payload;
		Get_MAC(rx_value, (uint8_t *)MAC);
		DEBUG_INFO ("MAC: %02x: %02x: %02x: %02x: %02x: %02x\r\n", MAC[0], MAC[1], MAC[2],MAC[3],MAC[4],MAC[5]);
		get_jig_info = true;
		test_res.result.rs232 = 1;
		break;
	case MIN_ID_RS232_ESP32_RESET:
		test_res.result.test_wd_ok = 1;
		test_res.result.rs232 = 1;
		break;
	default:
//		test_res.result.rs232 = 0;
		break;
	}
}
bool RS232_tx (void *ctx, uint8_t byte)
{
	(void)ctx;
	putChar (UART5, byte);
	return true;
}

void volTest(void)
{
	DEBUG_VERBOSE ("VOL TESTING ENTER \r\n");
	uint8_t res_cnt;
	uint16_t VolRes[2];
	for (uint8_t i = 0; i < 2; i ++)
	{
		VolRes [i] = (ADCScan[i]*3300/4095);
		VolRes [i] = VolRes[i] *2;
	}
	DEBUG_VERBOSE ("VSYS : %d mV\r\n", VolRes [0]);
	DEBUG_VERBOSE ("3V3 : %d mV\r\n", VolRes [1]);
//	DEBUG_VERBOSE ("V5v : %d mV\r\n", VolRes [2]);
//	DEBUG_INFO ("V3v3 : %d mV\r\n", VolRes [3]);
//	DEBUG_INFO ("V1v8 : %d mV\r\n", VolRes [4]);
//	DEBUG_INFO ("Vsys : %d mV\r\n", VolRes [5]);`
	res_cnt = 0;
//	if (voltage_info.v4v2_min <= VolRes[0] && VolRes[0] <= voltage_info.v4v2_max)
//	{
//		test_res.result.vgsm4v2_ok = 1;
//		res_cnt++;
//	}
//	else
//	{
//		test_res.result.vgsm4v2_ok = 0;
//	}
//	if (voltage_info.vbat_min <= VolRes[1] && VolRes[1] <= voltage_info.vbat_max)
//	{
//		test_res.result.vbat_ok = 1;
//		res_cnt++;
//	}
//	else
//	{
//		test_res.result.vbat_ok = 0;
//		res_cnt++;
//	}
//	if (voltage_info.v5v_min <= VolRes[2] && VolRes[2] <= voltage_info.v5v_max)
//	{
//		test_res.result.v5v_ok = 1;
//		res_cnt++;
//	}
//	else
//	{
//		test_res.result.v5v_ok = 0;
//	}
	if (voltage_info.v3v3_min <= VolRes[1] && VolRes[1] <= voltage_info.v3v3_max)
	{
		test_res.result.v3v3_ok = 1;
		res_cnt++;
	}
	else
	{
		test_res.result.v3v3_ok = 0;
	}
//	if (voltage_info.v1v8_min <= VolRes[4] && VolRes[4] <= voltage_info.v1v8_max)
//	{
//		test_res.result.v1v8_ok = 1;
//		res_cnt++;
//	}
//	else
//	{
//		test_res.result.v1v8_ok = 0;
//	}
	if (voltage_info.vsys_min <= VolRes[0] && VolRes[0] <= voltage_info.vsys_max)
	{
		test_res.result.vsys_ok = 1;
		res_cnt++;
	}
	else
	{
		test_res.result.vsys_ok = 0;
	}
	if (res_cnt == 2)
	{
//		return true;
		DEBUG_INFO ("VOLTAGE OK\r\n");
	}
	else
	{
		DEBUG_INFO ("VOLTAGE FAIL \r\n");
	}
//	return false;
}

bool PassTest (jig_value_t * value)
{
	if (strlen (value->gsm_imei) >= 15)
	{
		test_res.result.sim_ok = 1;
		DEBUG_INFO ("SIM OK \r\n");
	}
	else
	{
		test_res.result.sim_ok = 0;
		DEBUG_INFO ("SIM NOT OK \r\n");
	}
	if (25 <= value->temperature && value->temperature <=50)
	{
		test_res.result.temper_ok = 1;
		DEBUG_INFO ("TEMPER IS OK \r\n");
	}
	else
	{
		test_res.result.temper_ok = 0;
		DEBUG_INFO ("TEMPER IS not OK \r\n");
	}
	if (test_res.result.rs232
		&& test_res.result.rs485
		&& test_res.result.relay0_ok
		&& test_res.result.relay1_ok
		&& test_res.result.v1v8_ok
		&& test_res.result.v3v3_ok
		&& test_res.result.vbat_ok
		&& test_res.result.vsys_ok
		&& test_res.result.sim_ok
		&& test_res.result.test_wd_ok
		&& test_res.result.temper_ok
		)
	{
		allPassed = true;
		DEBUG_INFO ("ALL TEST RESULT PASS \r\n");
		return true;
	}
	else
	{
		allPassed = false;
		return false;
	}
	return 0;
}

//copy lien tuc gia tri tu led_detect sang led_detect_final
// kiem tra sau 3s neu chua dat thi coi nhu la chua dat

void check_led_status(void)
{

	led_status[LR1] = HAL_GPIO_ReadPin (IN_LR1_GPIO_Port, IN_LR1_Pin);
	led_status[LR2] = HAL_GPIO_ReadPin (IN_LR2_GPIO_Port, IN_LR2_Pin);
	led_status[LR3] = HAL_GPIO_ReadPin (IN_LR3_GPIO_Port, IN_LR3_Pin);
	led_status[LR4] = HAL_GPIO_ReadPin (IN_LR4_GPIO_Port, IN_LR4_Pin);
	led_status[LR5] = HAL_GPIO_ReadPin (IN_LR5_GPIO_Port, IN_LR5_Pin);
	led_status[LR6] = HAL_GPIO_ReadPin (IN_LR6_GPIO_Port, IN_LR6_Pin);
	led_status[LB1] = HAL_GPIO_ReadPin (IN_LB1_GPIO_Port, IN_LB1_Pin);
	led_status[LB2] = HAL_GPIO_ReadPin (IN_LB2_GPIO_Port, IN_LB2_Pin);
	led_status[LB3] = HAL_GPIO_ReadPin (IN_LB2_GPIO_Port, IN_LB3_Pin);
	led_status[LB4] = HAL_GPIO_ReadPin (IN_LB2_GPIO_Port, IN_LB4_Pin);
	led_status[LB5] = HAL_GPIO_ReadPin (IN_LB2_GPIO_Port, IN_LB5_Pin);
	led_status[LB6] = HAL_GPIO_ReadPin (IN_LB2_GPIO_Port, IN_LB6_Pin);
	for (uint8_t i = LR1; i < 6; i++)
	{
		if ((led_status [i] == 0) && (led_status [i + 6] == 0))
		{
			led_detect.led_res |= (1 << i );
		}
		else
		{
			led_detect.led_res &= ~(1 << i);
		}
	}
}

/**********************************    BUTTON APP FUNCTION         ******************************************/
void button_initialize(uint32_t button_num)
{

}

uint32_t btn_read(uint32_t pin)
{
    if (pin == 0)
    {
        return HAL_GPIO_ReadPin(BT_IN_GPIO_Port, BT_IN_Pin);
    }
    return 1;
//    else if (pin == 1)
//    {
//	return HAL_GPIO_ReadPin(KEY1_GPIO_Port, KEY1_Pin);
//    }
//    return HAL_GPIO_ReadPin(KEY3_GPIO_Port, KEY3_Pin);
}

void on_btn_pressed(int number, int event, void * pData)
{
    DEBUG_INFO("On button %d pressed\r\n", number);
    if (number == 0)
    {
        xEventGroupSetBits(m_button_event_group, BIT_EVENT_GROUP_BT_IN_PRESSED);
    }
//    else if (number == 1)
//    {
//        xEventGroupSetBits(m_button_event_group, BIT_EVENT_GROUP_KEY_1_PRESSED);
//    }
//    else
//    {
//        //xEventGroupSetBits(m_button_event_group, BIT_EVENT_GROUP_BUTTON_1_PRESSED);
//    }
}

void on_btn_release(int number, int event, void * pData)
{
    DEBUG_VERBOSE("On button %d release\r\n", number);
    if (number == 0)
    {
        xEventGroupClearBits(m_button_event_group, BIT_EVENT_GROUP_BT_IN_PRESSED);
    }
//    else if (number == 1)
//    {
//        xEventGroupClearBits(m_button_event_group, BIT_EVENT_GROUP_KEY_1_PRESSED);
//    }
//    else if (number == 2)
//    {
//      xEventGroupClearBits(m_button_event_group, BIT_EVENT_GROUP_BUTTON_2_PRESSED);
//    }
}

void on_btn_hold(int number, int event, void * pData)
{
    DEBUG_INFO("On button %d pair hold, enter pair mode\r\n", number);
}

static void on_btn_hold_so_long(int index, int event, void * pData)
{
    DEBUG_INFO("Button hold so long\r\n");
}
/*******************************************************************/

//******************************************  SNTP FUNCTION *******************************************************//
static void convert_second_to_date_time(uint32_t sec, date_time_t *t, uint8_t Calyear)
{
    uint16_t day;
    uint8_t year;
    uint16_t days_of_year;
    uint8_t leap400;
    uint8_t month;

    t->second = sec % 60;
    sec /= 60;
    t->minute = sec % 60;
    sec /= 60;
    t->hour = sec % 24;

    if (Calyear == 0)
        return;

    day = (uint16_t)(sec / 24);

    year = FIRSTYEAR % 100;                   // 0..99
    leap400 = 4 - ((FIRSTYEAR - 1) / 100 & 3); // 4, 3, 2, 1

    for (;;)
    {
        days_of_year = 365;
        if ((year & 3) == 0)
        {
            days_of_year = 366; // leap year
            if (year == 0 || year == 100 || year == 200)
            { // 100 year exception
                if (--leap400)
                { // 400 year exception
                    days_of_year = 365;
                }
            }
        }
        if (day < days_of_year)
        {
            break;
        }
        day -= days_of_year;
        year++; // 00..136 / 99..235
    }
    t->year = year + FIRSTYEAR / 100 * 100 - 2000; // + century
    if (days_of_year & 1 && day > 58)
    {          // no leap year and after 28.2.
        day++; // skip 29.2.
    }

    for (month = 1; day >= day_in_month[month - 1]; month++)
    {
        day -= day_in_month[month - 1];
    }

    t->month = month; // 1..12
    t->day = day + 1; // 1..31
}

static uint32_t convert_date_time_to_second(date_time_t *t)
{
    uint8_t i;
    uint32_t result = 0;
    uint16_t idx, year;

    year = t->year + 2000;

    /* Calculate days of years before */
    result = (uint32_t)year * 365;
    if (t->year >= 1)
    {
        result += (year + 3) / 4;
        result -= (year - 1) / 100;
        result += (year - 1) / 400;
    }

    /* Start with 2000 a.d. */
    result -= 730485UL;

    /* Make month an array index */
    idx = t->month - 1;

    /* Loop thru each month, adding the days */
    for (i = 0; i < idx; i++)
    {
        result += day_in_month[i];
    }

    /* Leap year? adjust February */
    if (year % 400 == 0 || (year % 4 == 0 && year % 100 != 0))
    {
        ;
    }
    else
    {
        if (t->month > 2)
        {
            result--;
        }
    }

    /* Add remaining days */
    result += t->day;

    /* Convert to seconds, add all the other stuff */
//    if (year < 2000)
//    {
//	    result = (result - 1) * 86400L + (uint32_t)t->hour * 3600 +
//	             (uint32_t)t->minute * 60 + t->second;
//	}
//	else
//	{
//		result = (result-2) * 86400L + (uint32_t)t->hour * 3600 +
//             (uint32_t)t->minute * 60 + t->second;
//	}
    result = (result - 1) * 86400L + (uint32_t)t->hour * 3600 +
    	             (uint32_t)t->minute * 60 + t->second;
    return result;
}

void lwip_sntp_recv_cb (uint32_t time)
{

	if (time == 0)
	{
		DEBUG_INFO ("NTP ERROR \r\n");
	}
	else
	{
//		reInitRTC()
		DEBUG_INFO (" GOT TIME : it's been %u second from 1970\r\n", time);

		time_t rawtime = time;
		struct tm ts;

		// Format time, "ddd yyyy-mm-dd hh:mm:ss zzz"
		ts = *localtime(&rawtime);

		DEBUG_INFO("Time now: %02d:%02d:%02d  %02d-%02d-%d\r\n", ts.tm_hour, ts.tm_min, ts.tm_sec, ts.tm_mday, ts.tm_mon + 1, ts.tm_year + 1900);

		date_time.year = (ts.tm_year + 1900) % 2000; //year - 1900
		date_time.month = ts.tm_mon + 1;             // month, where 0 = jan
		date_time.day = ts.tm_mday;                  // day of the month
		date_time.hour = ts.tm_hour;
		date_time.minute = ts.tm_min;
		date_time.second = ts.tm_sec;

		uint32_t time_buff = convert_date_time_to_second (&date_time) + 25200;// time for gmt +7

		convert_second_to_date_time (time_buff, &date_time, 1);

		DEBUG_INFO ("TIME NOW IS: %d:%d:%d %d-%d-%d\r\n", date_time.hour, date_time.minute, date_time.second, date_time.day,date_time.month, (date_time.year + 2000));
		sTime.Hours = date_time.hour;
		sTime.Minutes = date_time.minute;
		sTime.Seconds = date_time.second;
		sDate.Year = date_time.year;
		sDate.Month = date_time.month;
		sDate.Date = date_time.day;
		reInitRTC (sTime,sDate);
		HAL_RTC_GetTime (&hrtc, &sTime, RTC_FORMAT_BIN);
		HAL_RTC_GetDate (&hrtc, &sDate, RTC_FORMAT_BIN);
		DEBUG_INFO ("GET TIME: %d: %d: %d \r\n", (uint8_t)(sTime.Hours), (uint8_t)(sTime.Minutes),(uint8_t)(sTime.Seconds));
		DEBUG_INFO ("GET date: %d: %d: %d \r\n", (uint8_t)(sDate.Date), (uint8_t)(sDate.Month),(uint8_t)(sDate.Year));
//		uint32_t timenew = convert_date_time_to_second (&date_time);
//		DEBUG_INFO ("TIME CALCULATE: %u", timenew);
	}
}

static void initialize_stnp(void)
{
    static bool sntp_start = false;
    if (sntp_start == false)
    {
        sntp_start = true;

        sntp_setoperatingmode(SNTP_OPMODE_POLL);
        sntp_setservername(0, "pool.ntp.org");
        sntp_init();
        DEBUG_INFO("Initialize stnp\r\n");
    }
}

//************************************************************************//
// ************************* TIME RTC*********************************//
void reInitRTC ( RTC_TimeTypeDef sTime, RTC_DateTypeDef sDate)
{
	  /** Initialize RTC Only
	  */
	  /* USER CODE BEGIN Check_RTC_BKUP */

	  /* USER CODE END Check_RTC_BKUP */

	  /** Initialize RTC and set the Time and Date
	  */

	  if (HAL_RTC_SetTime(&hrtc, &sTime, RTC_FORMAT_BIN) != HAL_OK)
	  {
		  DEBUG_ERROR ("CAN'T SET TIME \r\n");
	    Error_Handler();
	  }

	  if (HAL_RTC_SetDate(&hrtc, &sDate, RTC_FORMAT_BIN) != HAL_OK)
	  {
		  DEBUG_ERROR ("CAN'T SET date \r\n");
	    Error_Handler();
	  }
}
//*****************************************************************//

//*********************** json encode*********************************//
int16_t json_build(jig_value_t *value, func_test_t * test, char *json_str)
{
	char mac_str[18];
	int16_t index = 0;

	index += sprintf (json_str+index, "[{\"timestamp\":%lu,", 				value ->timestamp);
	index += sprintf (json_str+index, "\"DeviceType\":\"%s\",", 			value ->device_type ? "B02":"B01");
	index += sprintf (json_str+index, "\"FirmwareVersion\":\"%d.%d.%d\",",	value ->fw_version[0],value ->fw_version[1],value ->fw_version[2] );
	index += sprintf (json_str+index, "\"HardwardVersion\":\"%d.%d.%d\",",	value ->hw_version[0],value ->hw_version[1],value ->hw_version[2] );
	index += sprintf (json_str+index, "\"GsmIMEI\":\"%s\",", 				value ->gsm_imei);
	sprintf (mac_str, "%02x:%02x:%02x:%02x:%02x:%02x",	value->mac[0],
														value->mac[1],
														value->mac[2],
														value->mac[3],
														value->mac[4],
														value->mac[5]);
//	make_string_from_mac (mac_str);
	index += sprintf (json_str+index, "\"MacJIG\":\"%s\",", 			mac_str);
	index += sprintf (json_str+index, "\"ErrorResults\":{");
	index += sprintf (json_str+index, "\"sim\":%s,", 					test->result.sim_ok ? "true" : "false");
	index += sprintf (json_str+index, "\"vGsm4V2\":%s,", 				test ->result.vgsm4v2_ok ? "true" : "false");
	index += sprintf (json_str+index, "\"eth\":%s,", 					value ->peripheral.name.eth ? "true" : "false");
	index += sprintf (json_str+index, "\"wifi\":%s,", 					value ->peripheral.name.wifi ? "true" : "false");
	index += sprintf (json_str+index, "\"server\":%s,", 				value ->peripheral.name.server ? "true" : "false");
//	sprintf (json_str_buff, "\"GSM status\":%d,\r\n", 				value ->peripheral.name.gsm);

	index += sprintf (json_str+index, "\"mainPower\":%s,", 				value ->peripheral.name.main_power_pass ? "true" : "false");
	index += sprintf (json_str+index, "\"backupPower\":%s,", 			value ->peripheral.name.backup_power_pass? "true" : "false");
	index += sprintf (json_str+index, "\"buttonTest\":%s,", 			value ->peripheral.name.button_pass? "true" : "false");
	index += sprintf (json_str+index, "\"input1\":%s,",					value->peripheral.name.input0_pass ? "true" : "false");
	index += sprintf (json_str+index, "\"input2\":%s,",					value->peripheral.name.input1_pass ? "true" : "false");
	index += sprintf (json_str+index, "\"input3\":%s,",					value->peripheral.name.input2_pass ? "true" : "false");
	index += sprintf (json_str+index, "\"input4\":%s,",					value->peripheral.name.input3_pass ? "true" : "false");
	index += sprintf (json_str+index, "\"temperature\":%s,", 			test->result.temper_ok? "true" : "false");
//	index += sprintf (json_str+index, "\"charge\":%s,", 				test->result.charge_ok? "true" : "false");
	index += sprintf (json_str+index, "\"alarmIn\":%s,", 				test->result.alarm_ok? "true" : "false");
	index += sprintf (json_str+index, "\"faultIn\":%s,", 				test->result.fault_ok? "true" : "false");
//	index += sprintf (json_str+index, "\"sosButton\":%s,", 				test->result.sosButton_ok? "true" : "false");
	index += sprintf (json_str+index, "\"relay0\":%s,", 				test->result.relay0_ok? "true" : "false");
	index += sprintf (json_str+index, "\"relay1\":%s,", 				test->result.relay1_ok? "true" : "false");
	index += sprintf (json_str+index, "\"watchdog\":%s,", 				test->result.test_wd_ok? "true" : "false");
	index += sprintf (json_str+index, "\"vbat\":%s,", 					test->result.vbat_ok? "true" : "false");
	index += sprintf (json_str+index, "\"v1v8\":%s,", 					test->result.v1v8_ok? "true" : "false");
	index += sprintf (json_str+index, "\"v3v3\":%s,", 					test->result.v3v3_ok? "true" : "false");
	index += sprintf (json_str+index, "\"vsys\":%s,", 					test->result.vsys_ok? "true" : "false");
	index += sprintf (json_str+index, "\"led1\":%s,", 					value->led_result.res.led1_ok? "true" : "false");
	index += sprintf (json_str+index, "\"led2\":%s,", 					value->led_result.res.led2_ok? "true" : "false");
	index += sprintf (json_str+index, "\"led3\":%s,", 					value->led_result.res.led3_ok? "true" : "false");
	index += sprintf (json_str+index, "\"led4\":%s,", 					value->led_result.res.led4_ok? "true" : "false");
	index += sprintf (json_str+index, "\"led5\":%s,", 					value->led_result.res.led5_ok? "true" : "false");
	index += sprintf (json_str+index, "\"led6\":%s,", 					value->led_result.res.led6_ok? "true" : "false");
	index += sprintf (json_str+index, "\"allPassed\":%s}}]", 			allPassed? "true" : "false");
	return index;
}
/* USER CODE END Application */
